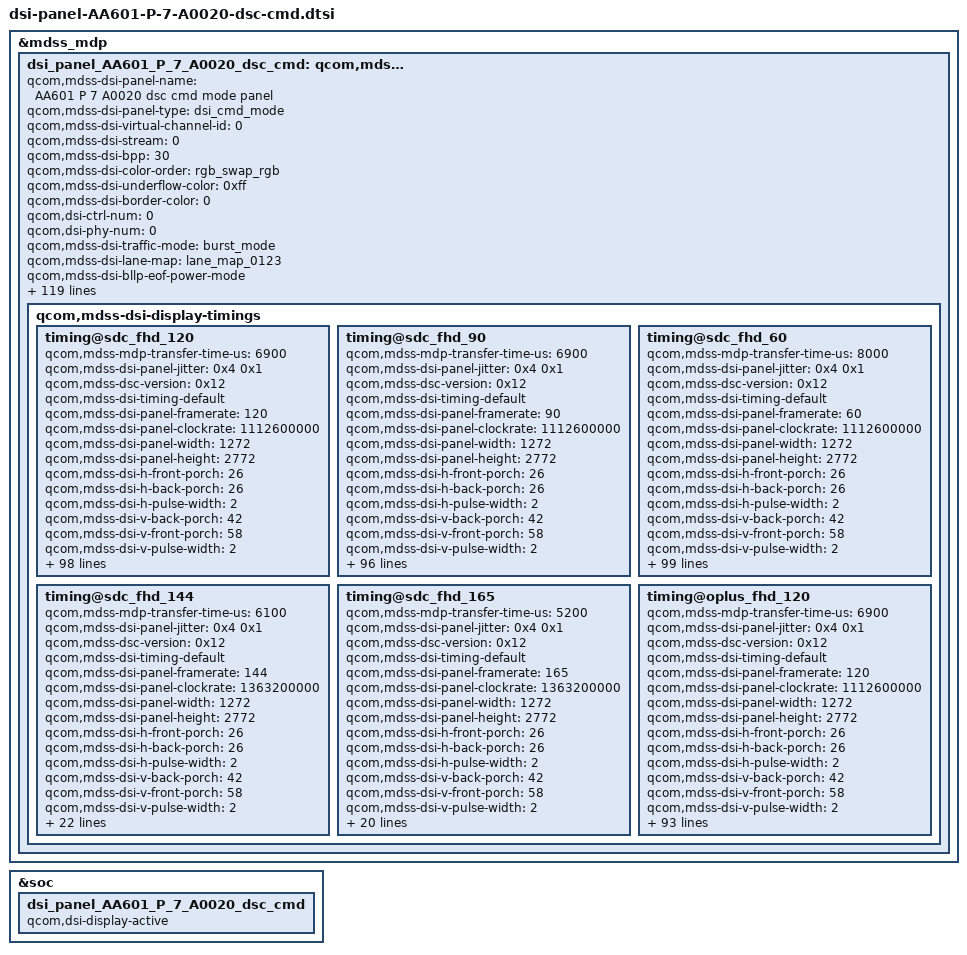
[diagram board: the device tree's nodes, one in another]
&mdss_mdp {
	dsi_panel_AA601_P_7_A0020_dsc_cmd: qcom,mdss_dsi_panel_AA601_P_7_A0020_dsc_cmd {
		qcom,mdss-dsi-panel-name = "AA601 P 7 A0020 dsc cmd mode panel";
		qcom,mdss-dsi-panel-type = "dsi_cmd_mode";
		qcom,mdss-dsi-virtual-channel-id = <0>;
		qcom,mdss-dsi-stream = <0>;
		qcom,mdss-dsi-bpp = <30>;
		qcom,mdss-dsi-color-order = "rgb_swap_rgb";
		qcom,mdss-dsi-underflow-color = <0xff>;
		qcom,mdss-dsi-border-color = <0>;
		qcom,dsi-ctrl-num = <0>;
		qcom,dsi-phy-num = <0>;
		qcom,mdss-dsi-traffic-mode = "burst_mode";
		qcom,mdss-dsi-lane-map = "lane_map_0123";
		qcom,mdss-dsi-bllp-eof-power-mode;
		qcom,mdss-dsi-bllp-power-mode;
		qcom,mdss-dsi-lane-0-state;
		qcom,mdss-dsi-lane-1-state;
		qcom,mdss-dsi-lane-2-state;
		qcom,mdss-dsi-lane-3-state;
		qcom,mdss-dsi-dma-trigger = "trigger_sw";
		qcom,mdss-dsi-dma-schedule-line = <1>;
		qcom,mdss-dsi-dma-schedule-window = <10>;
		qcom,mdss-dsi-mdp-trigger = "none";
		qcom,mdss-dsi-reset-sequence = <1 2>, <0 5>, <1 25>;
		qcom,mdss-dsi-te-pin-select = <1>;
		qcom,mdss-dsi-te-dcs-command = <1>;
		qcom,mdss-pan-physical-width-dimension = <71>;
		qcom,mdss-pan-physical-height-dimension = <157>;
		qcom,mdss-dsi-init-delay-us = <1000>;
		qcom,mdss-dsi-te-check-enable;
		qcom,mdss-dsi-te-using-te-pin;
		qcom,mdss-dsi-lp11-init;
		qcom,mdss-dsi-wr-mem-start = <0x2c>;
		qcom,mdss-dsi-wr-mem-continue = <0x3c>;
		qcom,mdss-dsi-panel-jitter = <0x4 0x1>;
		qcom,mdss-bl-high2bit;
		/* HDR Setting */
		qcom,mdss-dsi-panel-hdr-enabled;
		qcom,mdss-dsi-panel-hdr-color-primaries = <15635 16450 34000 16000 13250 34500 7500 3000>;
		//update for [MPC15]android.mediapc.cts.PerformanceClassTest#testDisplayHdr pass
		//qcom,mdss-dsi-panel-peak-brightness = <5400000>;
		qcom,mdss-dsi-panel-peak-brightness = <20000000>;
		qcom,mdss-dsi-panel-average-brightness = <2000000>;
		qcom,mdss-dsi-panel-blackness-level = <4000>;


		qcom,mdss-dsi-display-timings {
			timing@sdc_fhd_120 {
				#include "dsi-panel-AA601-P-7-A0020-common.dtsi"
				#include "dsi-panel-AA601-P-7-A0020-loading-effect.dtsi"
				qcom,mdss-mdp-transfer-time-us = <6900>;
				qcom,mdss-dsi-panel-jitter = <0x4 0x1>;
				qcom,mdss-dsc-version = <0x12>;
				qcom,mdss-dsi-timing-default;
				qcom,mdss-dsi-panel-framerate = <120>;
				qcom,mdss-dsi-panel-clockrate = <1112600000>;
				qcom,mdss-dsi-panel-width = <1272>;
				qcom,mdss-dsi-panel-height = <2772>;

				qcom,mdss-dsi-h-front-porch = <26>;
				qcom,mdss-dsi-h-back-porch = <26>;
				qcom,mdss-dsi-h-pulse-width = <2>;
				qcom,mdss-dsi-v-back-porch = <42>;
				qcom,mdss-dsi-v-front-porch = <58>;
				qcom,mdss-dsi-v-pulse-width = <2>;
				qcom,mdss-dsi-h-sync-pulse = <0>;

				oplus,ofp-need-to-sync-data-in-aod-unlocking;
				oplus,ofp-aod-off-insert-black-frame = <1>;
				oplus,ofp-aod-off-black-frame-total-time = <42>;
				oplus,ofp-need-to-separate-backlight;
				oplus,ofp-backlight-on-period = <1>;

				qcom,mdss-dsi-timing-switch-command = [
					39 00 00 40 00 00 04 FF 5A A5 00
					15 00 00 40 00 00 02 60 00 //120hz 3 pulse
					15 00 00 40 00 00 02 7D 00
					39 00 00 40 00 00 04 FF 5A A5 2D
					39 00 00 40 00 00 03 83 00 00
					15 00 00 40 00 00 02 F2 00
					39 00 00 00 00 00 04 FF 5A A5 00
				];

				qcom,mdss-dsi-timing-switch-compensation-command = [
					39 00 00 40 00 00 04 FF 5A A5 08 //Page 8
					15 00 00 40 00 00 02 98 02 //Disable CMD FIFO reset
					39 00 00 40 00 00 04 FF 5A A5 4F //Page 4F
					15 00 00 40 00 00 02 81 06
					15 00 00 40 00 00 02 88 78 //MFSC Start
					//D3G
					39 00 00 40 00 00 04 FF 5A A5 24
					39 00 00 40 00 00 06 C9 00 00 00 10 00
					39 00 00 40 00 00 04 FE 30 00 50
					39 00 00 40 00 00 06 CA 00 70 00 B0 01
					39 00 00 40 00 00 04 FE 00 01 30
					39 00 00 40 00 00 06 CB 01 73 01 AD 01
					39 00 00 40 00 00 04 FE F0 02 70
					39 00 00 40 00 00 06 CC 02 F0 03 50 03
					39 00 00 40 00 00 04 FE F0 04 70
					39 00 00 40 00 00 06 CD 04 F0 06 E0 08
					39 00 00 40 00 00 04 FE F0 0A 00
					39 00 00 40 00 00 06 CE 0B A0 0C D0 0D
					39 00 00 40 00 00 04 FE C0 0F F0
					39 00 00 40 00 00 04 FF 5A A5 4F //Page 4F
					15 00 00 40 00 00 02 8A 78 //MFSC Start
					//Mode control
					39 00 00 40 00 00 04 FF 5A A5 00 //Page 0
					15 00 00 40 00 00 02 60 00 //120HZ
					15 00 00 40 00 00 02 7D 00
					39 00 00 40 00 00 04 FF 5A A5 2D //Page 2D
					39 00 00 40 00 00 03 83 00 00 //Skip 0
					15 00 00 40 00 00 02 F2 00
					//D3G
					39 00 00 40 00 00 04 FF 5A A5 24
					39 00 00 40 00 00 06 C9 00 00 00 10 00
					39 00 00 40 00 00 04 FE 30 00 50
					39 00 00 40 00 00 06 CA 00 70 00 B0 00
					39 00 00 40 00 00 04 FE F0 01 30
					39 00 00 40 00 00 06 CB 01 70 01 B0 01
					39 00 00 40 00 00 04 FE F0 02 70
					39 00 00 40 00 00 06 CC 02 F0 03 70 03
					39 00 00 40 00 00 04 FE F0 04 70
					39 00 00 40 00 00 06 CD 04 F0 06 F0 08
					39 00 00 40 00 00 04 FE F0 0A 00
					39 00 00 40 00 00 06 CE 0B A0 0C D0 0E
					39 00 00 40 00 00 04 FE 10 0F F0
					//1 Gamma mode
					39 00 00 40 00 00 04 FF 5A A5 23
					15 00 00 40 00 00 02 CA 00
					15 00 00 40 00 00 02 CE 00
					//1 Gamma mode group
					39 00 00 40 00 00 04 FF 5A A5 24
					15 00 00 40 00 00 02 8D 42
					15 00 00 40 00 00 02 8E 74
					15 00 00 40 00 00 02 8F 50
					15 00 00 40 00 00 02 90 64
					//Normal DMR
					39 00 00 40 00 00 04 FF 5A A5 53
					15 00 00 40 00 00 02 F0 01
					15 00 00 40 00 00 02 00 00
					15 00 00 40 00 00 02 00 00
					15 00 00 40 00 00 02 00 00
					15 00 00 40 00 00 02 00 00
					15 00 00 40 00 00 02 00 00
					15 00 00 40 00 00 02 00 00
					15 00 00 40 00 00 02 00 00
					15 00 00 40 00 00 02 00 00
					39 00 00 40 00 00 04 FF 5A A5 63
					39 00 00 40 00 00 06 F1 20 20 20 20 20
					39 00 00 40 00 00 06 FE 20 00 00 00 00
					39 00 00 40 00 00 06 FE 00 00 00 00 00
					15 00 00 40 00 00 02 FE 00
					15 00 00 40 00 00 02 00 00
					15 00 00 40 00 00 02 00 00
					15 00 00 40 00 00 02 00 00
					15 00 00 40 00 00 02 00 00
					15 00 00 40 00 00 02 00 00
					39 00 00 40 00 00 06 F2 00 00 00 00 00
					39 00 00 40 00 00 06 FE 00 00 00 00 00
					39 00 00 40 00 00 06 FE 00 00 00 00 00
					15 00 00 40 00 00 02 FE 00
					15 00 00 40 00 00 02 00 00
					15 00 00 40 00 00 02 00 00
					15 00 00 40 00 00 02 00 00
					15 00 00 40 00 00 02 00 00
					15 00 00 40 00 00 02 00 00
					39 00 00 40 00 00 06 F3 00 00 00 00 00
					39 00 00 40 00 00 06 FE 00 20 20 20 20
					39 00 00 40 00 00 06 FE 00 00 00 00 00
					15 00 00 40 00 00 02 FE 00
					15 00 00 40 00 00 02 00 00
					15 00 00 40 00 00 02 00 00
					15 00 00 40 00 00 02 00 00
					15 00 00 40 00 00 02 00 00
					15 00 00 40 00 00 02 00 00
					39 00 00 40 00 00 06 F4 00 00 00 00 00
					39 00 00 40 00 00 06 FE 00 F0 F0 F0 F0
					39 00 00 40 00 00 06 FE 00 00 00 00 00
					15 00 00 40 00 00 02 FE 00
					15 00 00 40 00 00 02 00 00
					15 00 00 40 00 00 02 00 00
					15 00 00 40 00 00 02 00 00
					15 00 00 40 00 00 02 00 00
					15 00 00 40 00 00 02 00 00
					15 00 00 40 00 00 02 00 00
					15 00 00 40 00 00 02 00 00
					15 00 00 40 00 00 02 00 00
					39 00 00 40 00 00 04 FF 5A A5 53
					15 00 00 40 00 00 02 F0 00
					39 00 00 40 00 00 04 FF 5A A5 08 //Page 8
					15 00 00 40 00 00 02 98 A6 //Enable CMD FIFO reset
					39 00 00 40 00 00 04 FF 5A A5 00 //Page 0
					15 00 00 40 00 00 02 00 00 //Dummy write
					39 00 00 40 00 00 04 FF 5A A5 4F //Page 4F
					15 00 00 40 00 00 02 8B 78 //MFSC All done
					39 00 00 00 00 00 04 FF 5A A5 00
					/* wait for te and blocking one frame */
					39 00 00 20 00 00 04 FF 5A A5 00
				];

				qcom,mdss-dsi-on-command = [
					39 00 00 40 00 00 04 FF 5A A5 13
					15 00 00 40 00 00 02 F9 4C //HOLE OFF
					39 00 00 40 00 00 04 FF 5A A5 17
					15 00 00 40 00 00 02 A0 0E //RCN OFF
					//SPR in AP Start
					39 00 00 40 00 00 04 FF 5A A5 07
					15 00 00 40 00 00 02 8A 01
					39 00 00 40 00 00 03 8B 21 E0
					39 00 00 40 00 00 64 80 00 00 00 00 00 12 00 00 AB 30 80 0A D4 04 F8 00 16 02 7C 02 7C 02 00 02 59 00 20 02 2E 00 08 00 0D 04 F4 03 ED 18 00 10 F0 07 10 20 00 06 0F 0F 33 0E 1C 2A 38 46 54 62 69 70 77 79 7B 7D 7E 02 02 22 00 2A 40 2A BE 3A FC 3A FA 3A F8 3B 38 3B 78 3B B6 4B B6 4B F4 4B F4 6C 34 84 74 00 00 00 00 00 00
					39 00 00 40 00 00 64 81 00 00 00 00 00 12 00 00 AB 21 00 0A D4 04 F8 00 16 02 7C 02 7C 01 55 01 D7 00 0A 01 2D 00 35 00 0D 04 F4 16 3B 08 00 0C 00 07 10 20 00 06 0F 0F 33 0E 1C 2A 38 46 54 62 69 70 77 79 7B 7D 7E 00 82 11 40 19 C0 22 3E 32 7C 3A BA 3A F8 3B 38 3B 38 3B 76 4B 76 4B 74 4B 74 5B B4 73 F4 01 00 00 00 00 00
					39 00 00 40 00 00 04 FF 5A A5 07
					15 00 00 40 00 00 02 91 03 //Ycrcb
					39 00 00 40 00 00 04 FF 5A A5 14
					15 00 00 40 00 00 02 82 01 //SPR IN AP  ON
					39 00 00 40 00 00 04 FF 5A A5 14
					15 00 00 40 00 00 02 80 00 //DDIC SPR OFF
					//SPR in AP END
					39 00 00 40 00 00 04 FF 5A A5 4F
					15 00 00 40 00 00 02 81 06 //CMDQ SETTING
					39 00 00 40 00 00 04 FF 5A A5 08
					15 00 00 40 00 00 02 C8 62 //OTP don’t reload
					39 00 00 40 00 00 04 FF 5A A5 21
					15 00 00 40 00 00 02 A4 38 //Flash reload
					39 00 00 40 00 00 04 FF 5A A5 23
					15 00 00 40 00 00 02 85 15 //BC reload by OTP
					39 00 00 40 00 00 04 FF 5A A5 01
					15 00 00 40 00 00 02 FB 08 //Multi TE
					39 00 00 40 00 00 04 FF 5A A5 06
					15 00 00 40 00 00 02 A0 00 //ESD fixed
					15 00 00 40 00 00 02 C6 01 //1bit ESD check
					39 00 00 40 00 00 04 FF 5A A5 08
					15 00 00 40 00 00 02 D2 05
					15 00 00 40 00 00 02 D3 01
					/* FFC Setting */
					39 00 00 40 00 00 04 FF 5A A5 22
					39 00 00 40 00 00 08 D8 01 00 11 10 3C 18 18 //120HZ
					39 00 00 40 00 00 08 D9 00 FC 11 10 30 18 18 //144/165Hz
					39 00 00 40 00 00 0A DC 84 94 BB 00 20 C4 A1 CC 10
					15 00 00 40 00 00 02 DD 01
					15 00 00 40 00 00 02 DE F1
					15 00 00 40 00 00 02 DF 80
					39 00 00 40 00 00 07 E0 02 00 5F 21 00 28
					39 00 00 40 00 00 04 FF 5A A5 00
					15 00 00 40 00 00 02 7D 00
					39 00 00 40 00 00 04 FF 5A A5 00
					15 00 00 40 00 00 02 5E 01
					15 00 00 40 00 00 02 60 00
					15 00 00 40 00 00 02 61 07
					15 00 00 40 00 00 02 6D 01
					05 00 00 40 00 00 01 35
					15 00 00 00 00 00 02 53 20
					39 00 00 40 00 00 04 FF 5A A5 2D
					39 00 00 40 00 00 04 EC 01 FF 00 //SF en
					39 00 00 40 00 00 03 94 F5 00 // 144Hz SF mode2  165hz SF mode4
					39 00 00 00 00 00 04 FF 5A A5 00

					/* SC6027 */
					39 00 00 40 00 00 04 FF 5A A5 20
					15 00 00 40 00 00 02 C8 00
					15 00 00 40 00 00 02 C7 00
					39 00 00 40 00 00 04 FF 5A A5 00
					39 00 00 40 00 00 05 94 00 D0 00 00
					39 00 00 40 00 00 04 FF 5A A5 1F
					15 00 00 40 00 00 02 87 09
					15 00 00 40 00 00 02 88 34
					39 00 00 40 00 00 05 89 41 00 C4 01
					39 00 00 40 00 00 03 8A 8C 14
					39 00 00 40 00 00 05 8C 80 07 00 40
					15 00 00 40 00 00 02 8E 10
					15 00 00 40 00 00 02 95 00
					39 00 00 40 00 00 05 96 15 35 55 01
					39 00 00 40 00 00 19 83 00 0B 0A 0C 02 0F FF FF 0C 02 FF FF 00 FF 00 0B 00 FF FF FF FF FF FF FF
					39 00 00 40 00 00 19 8F 03 30 8C 19 0F 18 00 00 19 0F 00 00 00 00 02 30 02 00 00 00 00 00 00 00
					39 00 00 40 00 00 09 85 00 0B 0A FF FF FF FF FF
					39 00 00 40 00 00 09 91 03 30 24 00 00 00 00 00
					39 00 00 40 00 00 04 FF 5A A5 29
					39 00 00 40 00 00 09 82 74 2C 2A 2A 28 28 26 26
					39 00 00 40 00 00 09 83 24 24 22 22 20 20 1E 1E
					39 00 00 40 00 00 09 84 1C 1C 1A 1A 18 18 18 18
					39 00 00 40 00 00 07 85 18 18 18 18 18 18
					39 00 00 00 00 00 04 FF 5A A5 00
					/* 120hz 3 pulse */
					39 00 00 40 00 00 04 FF 5A A5 00
					15 00 00 40 00 00 02 60 00 //120hz 3 pulse
					15 00 00 40 00 00 02 7D 00
					39 00 00 40 00 00 04 FF 5A A5 2D
					39 00 00 40 00 00 03 83 00 00
					15 00 00 40 00 00 02 F2 00
					39 00 00 00 00 00 04 FF 5A A5 00

					05 00 00 00 78 00 01 11
					05 00 00 00 14 00 01 29
				];
			};
			timing@sdc_fhd_90 {
				#include "dsi-panel-AA601-P-7-A0020-common.dtsi"
				#include "dsi-panel-AA601-P-7-A0020-loading-effect.dtsi"
				qcom,mdss-mdp-transfer-time-us = <6900>;
				qcom,mdss-dsi-panel-jitter = <0x4 0x1>;
				qcom,mdss-dsc-version = <0x12>;
				qcom,mdss-dsi-timing-default;
				qcom,mdss-dsi-panel-framerate = <90>;
				qcom,mdss-dsi-panel-clockrate = <1112600000>;
				qcom,mdss-dsi-panel-width = <1272>;
				qcom,mdss-dsi-panel-height = <2772>;

				qcom,mdss-dsi-h-front-porch = <26>;
				qcom,mdss-dsi-h-back-porch = <26>;
				qcom,mdss-dsi-h-pulse-width = <2>;
				qcom,mdss-dsi-v-back-porch = <42>;
				qcom,mdss-dsi-v-front-porch = <58>;
				qcom,mdss-dsi-v-pulse-width = <2>;
				qcom,mdss-dsi-h-sync-pulse = <0>;

				oplus,ofp-need-to-sync-data-in-aod-unlocking;
				oplus,ofp-aod-off-insert-black-frame = <1>;
				oplus,ofp-aod-off-black-frame-total-time = <42>;
				oplus,ofp-need-to-separate-backlight;
				oplus,ofp-backlight-on-period = <1>;

				qcom,mdss-dsi-timing-switch-command = [
					39 00 00 40 00 00 04 FF 5A A5 00
					15 00 00 40 00 00 02 60 02 //90hz 3 pulse
					15 00 00 40 00 00 02 7D 00
					39 00 00 40 00 00 04 FF 5A A5 2D
					39 00 00 40 00 00 03 85 00 00
					39 00 00 00 00 00 04 FF 5A A5 00
				];

				qcom,mdss-dsi-timing-switch-compensation-command = [
					39 00 00 40 00 00 04 FF 5A A5 08 //Page 8
					15 00 00 40 00 00 02 98 02 //Disable CMD FIFO reset
					39 00 00 40 00 00 04 FF 5A A5 4F //Page 4F
					15 00 00 40 00 00 02 81 06
					15 00 00 40 00 00 02 88 78 //MFSC Start
					//D3G
					39 00 00 40 00 00 04 FF 5A A5 24
					39 00 00 40 00 00 06 C9 00 00 00 10 00
					39 00 00 40 00 00 04 FE 30 00 50
					39 00 00 40 00 00 06 CA 00 70 00 B0 01
					39 00 00 40 00 00 04 FE 00 01 30
					39 00 00 40 00 00 06 CB 01 73 01 AD 01
					39 00 00 40 00 00 04 FE F0 02 70
					39 00 00 40 00 00 06 CC 02 F0 03 50 03
					39 00 00 40 00 00 04 FE F0 04 70
					39 00 00 40 00 00 06 CD 04 F0 06 E0 08
					39 00 00 40 00 00 04 FE F0 0A 00
					39 00 00 40 00 00 06 CE 0B A0 0C D0 0D
					39 00 00 40 00 00 04 FE C0 0F F0
					39 00 00 40 00 00 04 FF 5A A5 4F //Page 4F
					15 00 00 40 00 00 02 8A 78 //MFSC Start
					//Mode control
					39 00 00 40 00 00 04 FF 5A A5 00 //Page 0
					15 00 00 40 00 00 02 60 02 //90HZ
					15 00 00 40 00 00 02 7D 00
					39 00 00 40 00 00 04 FF 5A A5 2D //Page 2D
					39 00 00 40 00 00 03 85 00 00 //Skip 0
					//D3G
					39 00 00 40 00 00 04 FF 5A A5 24
					39 00 00 40 00 00 06 C9 00 00 00 10 00
					39 00 00 40 00 00 04 FE 30 00 50
					39 00 00 40 00 00 06 CA 00 70 00 B0 00
					39 00 00 40 00 00 04 FE F0 01 30
					39 00 00 40 00 00 06 CB 01 70 01 B0 01
					39 00 00 40 00 00 04 FE F0 02 70
					39 00 00 40 00 00 06 CC 02 F0 03 70 03
					39 00 00 40 00 00 04 FE F0 04 70
					39 00 00 40 00 00 06 CD 04 F0 06 F0 08
					39 00 00 40 00 00 04 FE F0 0A 00
					39 00 00 40 00 00 06 CE 0B A0 0C D0 0E
					39 00 00 40 00 00 04 FE 10 0F F0
					//1 Gamma mode
					39 00 00 40 00 00 04 FF 5A A5 23
					15 00 00 40 00 00 02 CA 00
					15 00 00 40 00 00 02 CE 00
					//1 Gamma mode group
					39 00 00 40 00 00 04 FF 5A A5 24
					15 00 00 40 00 00 02 8D 42
					15 00 00 40 00 00 02 8E 74
					15 00 00 40 00 00 02 8F 50
					15 00 00 40 00 00 02 90 64
					//Normal DMR
					39 00 00 40 00 00 04 FF 5A A5 53
					15 00 00 40 00 00 02 F0 01
					15 00 00 40 00 00 02 00 00
					15 00 00 40 00 00 02 00 00
					15 00 00 40 00 00 02 00 00
					15 00 00 40 00 00 02 00 00
					15 00 00 40 00 00 02 00 00
					15 00 00 40 00 00 02 00 00
					15 00 00 40 00 00 02 00 00
					15 00 00 40 00 00 02 00 00
					39 00 00 40 00 00 04 FF 5A A5 63
					39 00 00 40 00 00 06 F1 20 20 20 20 20
					39 00 00 40 00 00 06 FE 20 00 00 00 00
					39 00 00 40 00 00 06 FE 00 00 00 00 00
					15 00 00 40 00 00 02 FE 00
					15 00 00 40 00 00 02 00 00
					15 00 00 40 00 00 02 00 00
					15 00 00 40 00 00 02 00 00
					15 00 00 40 00 00 02 00 00
					15 00 00 40 00 00 02 00 00
					39 00 00 40 00 00 06 F2 00 00 00 00 00
					39 00 00 40 00 00 06 FE 00 00 00 00 00
					39 00 00 40 00 00 06 FE 00 00 00 00 00
					15 00 00 40 00 00 02 FE 00
					15 00 00 40 00 00 02 00 00
					15 00 00 40 00 00 02 00 00
					15 00 00 40 00 00 02 00 00
					15 00 00 40 00 00 02 00 00
					15 00 00 40 00 00 02 00 00
					39 00 00 40 00 00 06 F3 00 00 00 00 00
					39 00 00 40 00 00 06 FE 00 20 20 20 20
					39 00 00 40 00 00 06 FE 00 00 00 00 00
					15 00 00 40 00 00 02 FE 00
					15 00 00 40 00 00 02 00 00
					15 00 00 40 00 00 02 00 00
					15 00 00 40 00 00 02 00 00
					15 00 00 40 00 00 02 00 00
					15 00 00 40 00 00 02 00 00
					39 00 00 40 00 00 06 F4 00 00 00 00 00
					39 00 00 40 00 00 06 FE 00 F0 F0 F0 F0
					39 00 00 40 00 00 06 FE 00 00 00 00 00
					15 00 00 40 00 00 02 FE 00
					15 00 00 40 00 00 02 00 00
					15 00 00 40 00 00 02 00 00
					15 00 00 40 00 00 02 00 00
					15 00 00 40 00 00 02 00 00
					15 00 00 40 00 00 02 00 00
					15 00 00 40 00 00 02 00 00
					15 00 00 40 00 00 02 00 00
					15 00 00 40 00 00 02 00 00
					39 00 00 40 00 00 04 FF 5A A5 53
					15 00 00 40 00 00 02 F0 00
					39 00 00 40 00 00 04 FF 5A A5 08 //Page 8
					15 00 00 40 00 00 02 98 A6 //Enable CMD FIFO reset
					39 00 00 40 00 00 04 FF 5A A5 00 //Page 0
					15 00 00 40 00 00 02 00 00 //Dummy write
					39 00 00 40 00 00 04 FF 5A A5 4F //Page 4F
					15 00 00 40 00 00 02 8B 78 //MFSC All done
					39 00 00 00 00 00 04 FF 5A A5 00
					/* wait for te and blocking one frame */
					39 00 00 20 00 00 04 FF 5A A5 00
				];

				qcom,mdss-dsi-on-command = [
					39 00 00 40 00 00 04 FF 5A A5 13
					15 00 00 40 00 00 02 F9 4C //HOLE OFF
					39 00 00 40 00 00 04 FF 5A A5 17
					15 00 00 40 00 00 02 A0 0E //RCN OFF
					//SPR in AP Start
					39 00 00 40 00 00 04 FF 5A A5 07
					15 00 00 40 00 00 02 8A 01
					39 00 00 40 00 00 03 8B 21 E0
					39 00 00 40 00 00 64 80 00 00 00 00 00 12 00 00 AB 30 80 0A D4 04 F8 00 16 02 7C 02 7C 02 00 02 59 00 20 02 2E 00 08 00 0D 04 F4 03 ED 18 00 10 F0 07 10 20 00 06 0F 0F 33 0E 1C 2A 38 46 54 62 69 70 77 79 7B 7D 7E 02 02 22 00 2A 40 2A BE 3A FC 3A FA 3A F8 3B 38 3B 78 3B B6 4B B6 4B F4 4B F4 6C 34 84 74 00 00 00 00 00 00
					39 00 00 40 00 00 64 81 00 00 00 00 00 12 00 00 AB 21 00 0A D4 04 F8 00 16 02 7C 02 7C 01 55 01 D7 00 0A 01 2D 00 35 00 0D 04 F4 16 3B 08 00 0C 00 07 10 20 00 06 0F 0F 33 0E 1C 2A 38 46 54 62 69 70 77 79 7B 7D 7E 00 82 11 40 19 C0 22 3E 32 7C 3A BA 3A F8 3B 38 3B 38 3B 76 4B 76 4B 74 4B 74 5B B4 73 F4 01 00 00 00 00 00
					39 00 00 40 00 00 04 FF 5A A5 07
					15 00 00 40 00 00 02 91 03 //Ycrcb
					39 00 00 40 00 00 04 FF 5A A5 14
					15 00 00 40 00 00 02 82 01 //SPR IN AP  ON
					39 00 00 40 00 00 04 FF 5A A5 14
					15 00 00 40 00 00 02 80 00 //DDIC SPR OFF
					//SPR in AP END
					39 00 00 40 00 00 04 FF 5A A5 4F
					15 00 00 40 00 00 02 81 06 //CMDQ SETTING
					39 00 00 40 00 00 04 FF 5A A5 08
					15 00 00 40 00 00 02 C8 62 //OTP don’t reload
					39 00 00 40 00 00 04 FF 5A A5 21
					15 00 00 40 00 00 02 A4 38 //Flash reload
					39 00 00 40 00 00 04 FF 5A A5 23
					15 00 00 40 00 00 02 85 15 //BC reload by OTP
					39 00 00 40 00 00 04 FF 5A A5 01
					15 00 00 40 00 00 02 FB 08 //Multi TE
					39 00 00 40 00 00 04 FF 5A A5 06
					15 00 00 40 00 00 02 A0 00 //ESD fixed
					15 00 00 40 00 00 02 C6 01 //1bit ESD check
					39 00 00 40 00 00 04 FF 5A A5 08
					15 00 00 40 00 00 02 D2 05
					15 00 00 40 00 00 02 D3 01
					/* FFC Setting */
					39 00 00 40 00 00 04 FF 5A A5 22
					39 00 00 40 00 00 08 D8 01 00 11 10 3C 18 18 //120HZ
					39 00 00 40 00 00 08 D9 00 FC 11 10 30 18 18 //144/165Hz
					39 00 00 40 00 00 0A DC 84 94 BB 00 20 C4 A1 CC 10
					15 00 00 40 00 00 02 DD 01
					15 00 00 40 00 00 02 DE F1
					15 00 00 40 00 00 02 DF 80
					39 00 00 40 00 00 07 E0 02 00 5F 21 00 28
					39 00 00 40 00 00 04 FF 5A A5 00
					15 00 00 40 00 00 02 7D 00
					39 00 00 40 00 00 04 FF 5A A5 00
					15 00 00 40 00 00 02 5E 01
					15 00 00 40 00 00 02 60 00
					15 00 00 40 00 00 02 61 07
					15 00 00 40 00 00 02 6D 01
					05 00 00 40 00 00 01 35
					15 00 00 00 00 00 02 53 20
					39 00 00 40 00 00 04 FF 5A A5 2D
					39 00 00 40 00 00 04 EC 01 FF 00 //SF en
					39 00 00 40 00 00 03 94 F5 00 // 144Hz SF mode2  165hz SF mode4
					39 00 00 00 00 00 04 FF 5A A5 00

					/* SC6027 */
					39 00 00 40 00 00 04 FF 5A A5 20
					15 00 00 40 00 00 02 C8 00
					15 00 00 40 00 00 02 C7 00
					39 00 00 40 00 00 04 FF 5A A5 00
					39 00 00 40 00 00 05 94 00 D0 00 00
					39 00 00 40 00 00 04 FF 5A A5 1F
					15 00 00 40 00 00 02 87 09
					15 00 00 40 00 00 02 88 34
					39 00 00 40 00 00 05 89 41 00 C4 01
					39 00 00 40 00 00 03 8A 8C 14
					39 00 00 40 00 00 05 8C 80 07 00 40
					15 00 00 40 00 00 02 8E 10
					15 00 00 40 00 00 02 95 00
					39 00 00 40 00 00 05 96 15 35 55 01
					39 00 00 40 00 00 19 83 00 0B 0A 0C 02 0F FF FF 0C 02 FF FF 00 FF 00 0B 00 FF FF FF FF FF FF FF
					39 00 00 40 00 00 19 8F 03 30 8C 19 0F 18 00 00 19 0F 00 00 00 00 02 30 02 00 00 00 00 00 00 00
					39 00 00 40 00 00 09 85 00 0B 0A FF FF FF FF FF
					39 00 00 40 00 00 09 91 03 30 24 00 00 00 00 00
					39 00 00 40 00 00 04 FF 5A A5 29
					39 00 00 40 00 00 09 82 74 2C 2A 2A 28 28 26 26
					39 00 00 40 00 00 09 83 24 24 22 22 20 20 1E 1E
					39 00 00 40 00 00 09 84 1C 1C 1A 1A 18 18 18 18
					39 00 00 40 00 00 07 85 18 18 18 18 18 18
					39 00 00 00 00 00 04 FF 5A A5 00
					/* 90hz 3 pulse */
					39 00 00 40 00 00 04 FF 5A A5 00
					15 00 00 40 00 00 02 60 02 //90hz 3 pulse
					15 00 00 40 00 00 02 7D 00
					39 00 00 40 00 00 04 FF 5A A5 2D
					39 00 00 40 00 00 03 85 00 00
					39 00 00 00 00 00 04 FF 5A A5 00

					05 00 00 00 78 00 01 11
					05 00 00 00 14 00 01 29
				];
			};
			timing@sdc_fhd_60 {
				#include "dsi-panel-AA601-P-7-A0020-common.dtsi"
				#include "dsi-panel-AA601-P-7-A0020-loading-effect.dtsi"
				qcom,mdss-mdp-transfer-time-us = <8000>;
				qcom,mdss-dsi-panel-jitter = <0x4 0x1>;
				qcom,mdss-dsc-version = <0x12>;
				qcom,mdss-dsi-timing-default;
				qcom,mdss-dsi-panel-framerate = <60>;
				qcom,mdss-dsi-panel-clockrate = <1112600000>;
				qcom,mdss-dsi-panel-width = <1272>;
				qcom,mdss-dsi-panel-height = <2772>;

				qcom,mdss-dsi-h-front-porch = <26>;
				qcom,mdss-dsi-h-back-porch = <26>;
				qcom,mdss-dsi-h-pulse-width = <2>;
				qcom,mdss-dsi-v-back-porch = <42>;
				qcom,mdss-dsi-v-front-porch = <58>;
				qcom,mdss-dsi-v-pulse-width = <2>;
				qcom,mdss-dsi-h-sync-pulse = <0>;

				oplus,ofp-need-to-sync-data-in-aod-unlocking;
				oplus,ofp-aod-off-insert-black-frame = <1>;
				oplus,ofp-aod-off-black-frame-total-time = <42>;
				oplus,ofp-need-to-separate-backlight;
				oplus,ofp-backlight-on-period = <1>;
				oplus,apollo-panel-async-bl-delay = <9000>;
				oplus,apollo-panel-vsync-width = <9000>;
				oplus,panel-pwm-switch-frame-delay = <9000>;

				qcom,mdss-dsi-timing-switch-command = [
					39 00 00 40 00 00 04 FF 5A A5 00
					15 00 00 40 00 00 02 60 00
					15 00 00 40 00 00 02 7D 00
					39 00 00 40 00 00 04 FF 5A A5 2D
					39 00 00 40 00 00 03 83 01 00
					15 00 00 40 00 00 02 F2 01
					39 00 00 00 00 00 04 FF 5A A5 00
				];

				qcom,mdss-dsi-timing-switch-compensation-command = [
					39 00 00 40 00 00 04 FF 5A A5 08 //Page 8
					15 00 00 40 00 00 02 98 02 //Disable CMD FIFO reset
					39 00 00 40 00 00 04 FF 5A A5 4F //Page 4F
					15 00 00 40 00 00 02 81 06
					15 00 00 40 00 00 02 88 78 //MFSC Start
					//D3G
					39 00 00 40 00 00 04 FF 5A A5 24
					39 00 00 40 00 00 06 C9 00 00 00 10 00
					39 00 00 40 00 00 04 FE 30 00 50
					39 00 00 40 00 00 06 CA 00 70 00 B0 01
					39 00 00 40 00 00 04 FE 00 01 30
					39 00 00 40 00 00 06 CB 01 73 01 AD 01
					39 00 00 40 00 00 04 FE F0 02 70
					39 00 00 40 00 00 06 CC 02 F0 03 50 03
					39 00 00 40 00 00 04 FE F0 04 70
					39 00 00 40 00 00 06 CD 04 F0 06 E0 08
					39 00 00 40 00 00 04 FE F0 0A 00
					39 00 00 40 00 00 06 CE 0B A0 0C D0 0D
					39 00 00 40 00 00 04 FE C0 0F F0
					39 00 00 40 00 00 04 FF 5A A5 4F //Page 4F
					15 00 00 40 00 00 02 8A 78 //MFSC Start
					//Mode control
					39 00 00 40 00 00 04 FF 5A A5 00 //Page 0
					15 00 00 40 00 00 02 60 00 //120HZ
					15 00 00 40 00 00 02 7D 00
					39 00 00 40 00 00 04 FF 5A A5 2D //Page 2D
					39 00 00 40 00 00 03 83 01 00 //Skip 60 Hz
					15 00 00 40 00 00 02 F2 01
					//D3G
					39 00 00 40 00 00 04 FF 5A A5 24
					39 00 00 40 00 00 06 C9 00 00 00 10 00
					39 00 00 40 00 00 04 FE 30 00 50
					39 00 00 40 00 00 06 CA 00 70 00 B0 00
					39 00 00 40 00 00 04 FE F0 01 30
					39 00 00 40 00 00 06 CB 01 70 01 B0 01
					39 00 00 40 00 00 04 FE F0 02 70
					39 00 00 40 00 00 06 CC 02 F0 03 70 03
					39 00 00 40 00 00 04 FE F0 04 70
					39 00 00 40 00 00 06 CD 04 F0 06 F0 08
					39 00 00 40 00 00 04 FE F0 0A 00
					39 00 00 40 00 00 06 CE 0B A0 0C D0 0E
					39 00 00 40 00 00 04 FE 10 0F F0
					//1 Gamma mode
					39 00 00 40 00 00 04 FF 5A A5 23
					15 00 00 40 00 00 02 CA 00
					15 00 00 40 00 00 02 CE 00
					//1 Gamma mode group
					39 00 00 40 00 00 04 FF 5A A5 24
					15 00 00 40 00 00 02 8D 42
					15 00 00 40 00 00 02 8E 74
					15 00 00 40 00 00 02 8F 50
					15 00 00 40 00 00 02 90 64
					//Normal DMR
					39 00 00 40 00 00 04 FF 5A A5 53
					15 00 00 40 00 00 02 F0 01
					15 00 00 40 00 00 02 00 00
					15 00 00 40 00 00 02 00 00
					15 00 00 40 00 00 02 00 00
					15 00 00 40 00 00 02 00 00
					15 00 00 40 00 00 02 00 00
					15 00 00 40 00 00 02 00 00
					15 00 00 40 00 00 02 00 00
					15 00 00 40 00 00 02 00 00
					39 00 00 40 00 00 04 FF 5A A5 63
					39 00 00 40 00 00 06 F1 20 20 20 20 20
					39 00 00 40 00 00 06 FE 20 00 00 00 00
					39 00 00 40 00 00 06 FE 00 00 00 00 00
					15 00 00 40 00 00 02 FE 00
					15 00 00 40 00 00 02 00 00
					15 00 00 40 00 00 02 00 00
					15 00 00 40 00 00 02 00 00
					15 00 00 40 00 00 02 00 00
					15 00 00 40 00 00 02 00 00
					39 00 00 40 00 00 06 F2 00 00 00 00 00
					39 00 00 40 00 00 06 FE 00 00 00 00 00
					39 00 00 40 00 00 06 FE 00 00 00 00 00
					15 00 00 40 00 00 02 FE 00
					15 00 00 40 00 00 02 00 00
					15 00 00 40 00 00 02 00 00
					15 00 00 40 00 00 02 00 00
					15 00 00 40 00 00 02 00 00
					15 00 00 40 00 00 02 00 00
					39 00 00 40 00 00 06 F3 00 00 00 00 00
					39 00 00 40 00 00 06 FE 00 20 20 20 20
					39 00 00 40 00 00 06 FE 00 00 00 00 00
					15 00 00 40 00 00 02 FE 00
					15 00 00 40 00 00 02 00 00
					15 00 00 40 00 00 02 00 00
					15 00 00 40 00 00 02 00 00
					15 00 00 40 00 00 02 00 00
					15 00 00 40 00 00 02 00 00
					39 00 00 40 00 00 06 F4 00 00 00 00 00
					39 00 00 40 00 00 06 FE 00 F0 F0 F0 F0
					39 00 00 40 00 00 06 FE 00 00 00 00 00
					15 00 00 40 00 00 02 FE 00
					15 00 00 40 00 00 02 00 00
					15 00 00 40 00 00 02 00 00
					15 00 00 40 00 00 02 00 00
					15 00 00 40 00 00 02 00 00
					15 00 00 40 00 00 02 00 00
					15 00 00 40 00 00 02 00 00
					15 00 00 40 00 00 02 00 00
					15 00 00 40 00 00 02 00 00
					39 00 00 40 00 00 04 FF 5A A5 53
					15 00 00 40 00 00 02 F0 00
					39 00 00 40 00 00 04 FF 5A A5 08 //Page 8
					15 00 00 40 00 00 02 98 A6 //Enable CMD FIFO reset
					39 00 00 40 00 00 04 FF 5A A5 00 //Page 0
					15 00 00 40 00 00 02 00 00 //Dummy write
					39 00 00 40 00 00 04 FF 5A A5 4F //Page 4F
					15 00 00 40 00 00 02 8B 78 //MFSC All done
					39 00 00 00 00 00 04 FF 5A A5 00
					/* wait for te and blocking one frame */
					39 00 00 20 00 00 04 FF 5A A5 00
				];

				qcom,mdss-dsi-on-command = [
					39 00 00 40 00 00 04 FF 5A A5 13
					15 00 00 40 00 00 02 F9 4C //HOLE OFF
					39 00 00 40 00 00 04 FF 5A A5 17
					15 00 00 40 00 00 02 A0 0E //RCN OFF
					//SPR in AP Start
					39 00 00 40 00 00 04 FF 5A A5 07
					15 00 00 40 00 00 02 8A 01
					39 00 00 40 00 00 03 8B 21 E0
					39 00 00 40 00 00 64 80 00 00 00 00 00 12 00 00 AB 30 80 0A D4 04 F8 00 16 02 7C 02 7C 02 00 02 59 00 20 02 2E 00 08 00 0D 04 F4 03 ED 18 00 10 F0 07 10 20 00 06 0F 0F 33 0E 1C 2A 38 46 54 62 69 70 77 79 7B 7D 7E 02 02 22 00 2A 40 2A BE 3A FC 3A FA 3A F8 3B 38 3B 78 3B B6 4B B6 4B F4 4B F4 6C 34 84 74 00 00 00 00 00 00
					39 00 00 40 00 00 64 81 00 00 00 00 00 12 00 00 AB 21 00 0A D4 04 F8 00 16 02 7C 02 7C 01 55 01 D7 00 0A 01 2D 00 35 00 0D 04 F4 16 3B 08 00 0C 00 07 10 20 00 06 0F 0F 33 0E 1C 2A 38 46 54 62 69 70 77 79 7B 7D 7E 00 82 11 40 19 C0 22 3E 32 7C 3A BA 3A F8 3B 38 3B 38 3B 76 4B 76 4B 74 4B 74 5B B4 73 F4 01 00 00 00 00 00
					39 00 00 40 00 00 04 FF 5A A5 07
					15 00 00 40 00 00 02 91 03 //Ycrcb
					39 00 00 40 00 00 04 FF 5A A5 14
					15 00 00 40 00 00 02 82 01 //SPR IN AP  ON
					39 00 00 40 00 00 04 FF 5A A5 14
					15 00 00 40 00 00 02 80 00 //DDIC SPR OFF
					//SPR in AP END
					39 00 00 40 00 00 04 FF 5A A5 4F
					15 00 00 40 00 00 02 81 06 //CMDQ SETTING
					39 00 00 40 00 00 04 FF 5A A5 08
					15 00 00 40 00 00 02 C8 62 //OTP don’t reload
					39 00 00 40 00 00 04 FF 5A A5 21
					15 00 00 40 00 00 02 A4 38 //Flash reload
					39 00 00 40 00 00 04 FF 5A A5 23
					15 00 00 40 00 00 02 85 15 //BC reload by OTP
					39 00 00 40 00 00 04 FF 5A A5 01
					15 00 00 40 00 00 02 FB 08 //Multi TE
					39 00 00 40 00 00 04 FF 5A A5 06
					15 00 00 40 00 00 02 A0 00 //ESD fixed
					15 00 00 40 00 00 02 C6 01 //1bit ESD check
					39 00 00 40 00 00 04 FF 5A A5 08
					15 00 00 40 00 00 02 D2 05
					15 00 00 40 00 00 02 D3 01
					/* FFC Setting */
					39 00 00 40 00 00 04 FF 5A A5 22
					39 00 00 40 00 00 08 D8 01 00 11 10 3C 18 18 //120HZ
					39 00 00 40 00 00 08 D9 00 FC 11 10 30 18 18 //144/165Hz
					39 00 00 40 00 00 0A DC 84 94 BB 00 20 C4 A1 CC 10
					15 00 00 40 00 00 02 DD 01
					15 00 00 40 00 00 02 DE F1
					15 00 00 40 00 00 02 DF 80
					39 00 00 40 00 00 07 E0 02 00 5F 21 00 28
					39 00 00 40 00 00 04 FF 5A A5 00
					15 00 00 40 00 00 02 7D 00
					39 00 00 40 00 00 04 FF 5A A5 00
					15 00 00 40 00 00 02 5E 01
					15 00 00 40 00 00 02 60 00
					15 00 00 40 00 00 02 61 07
					15 00 00 40 00 00 02 6D 01
					05 00 00 40 00 00 01 35
					15 00 00 00 00 00 02 53 20
					39 00 00 40 00 00 04 FF 5A A5 2D
					39 00 00 40 00 00 04 EC 01 FF 00 //SF en
					39 00 00 40 00 00 03 94 F5 00 // 144Hz SF mode2  165hz SF mode4
					39 00 00 00 00 00 04 FF 5A A5 00

					/* SC6027 */
					39 00 00 40 00 00 04 FF 5A A5 20
					15 00 00 40 00 00 02 C8 00
					15 00 00 40 00 00 02 C7 00
					39 00 00 40 00 00 04 FF 5A A5 00
					39 00 00 40 00 00 05 94 00 D0 00 00
					39 00 00 40 00 00 04 FF 5A A5 1F
					15 00 00 40 00 00 02 87 09
					15 00 00 40 00 00 02 88 34
					39 00 00 40 00 00 05 89 41 00 C4 01
					39 00 00 40 00 00 03 8A 8C 14
					39 00 00 40 00 00 05 8C 80 07 00 40
					15 00 00 40 00 00 02 8E 10
					15 00 00 40 00 00 02 95 00
					39 00 00 40 00 00 05 96 15 35 55 01
					39 00 00 40 00 00 19 83 00 0B 0A 0C 02 0F FF FF 0C 02 FF FF 00 FF 00 0B 00 FF FF FF FF FF FF FF
					39 00 00 40 00 00 19 8F 03 30 8C 19 0F 18 00 00 19 0F 00 00 00 00 02 30 02 00 00 00 00 00 00 00
					39 00 00 40 00 00 09 85 00 0B 0A FF FF FF FF FF
					39 00 00 40 00 00 09 91 03 30 24 00 00 00 00 00
					39 00 00 40 00 00 04 FF 5A A5 29
					39 00 00 40 00 00 09 82 74 2C 2A 2A 28 28 26 26
					39 00 00 40 00 00 09 83 24 24 22 22 20 20 1E 1E
					39 00 00 40 00 00 09 84 1C 1C 1A 1A 18 18 18 18
					39 00 00 40 00 00 07 85 18 18 18 18 18 18
					39 00 00 00 00 00 04 FF 5A A5 00
					/* 60hz 3 pulse */
					39 00 00 40 00 00 04 FF 5A A5 00
					15 00 00 40 00 00 02 60 00
					15 00 00 40 00 00 02 7D 00
					39 00 00 40 00 00 04 FF 5A A5 2D
					39 00 00 40 00 00 03 83 01 00
					15 00 00 40 00 00 02 F2 01
					39 00 00 00 00 00 04 FF 5A A5 00

					05 00 00 00 78 00 01 11
					05 00 00 00 14 00 01 29
				];
			};
			timing@sdc_fhd_144 {
				#include "dsi-panel-AA601-P-7-A0020-common.dtsi"
				#include "dsi-panel-AA601-P-7-A0020-loading-effect.dtsi"
				qcom,mdss-mdp-transfer-time-us = <6100>;
				qcom,mdss-dsi-panel-jitter = <0x4 0x1>;
				qcom,mdss-dsc-version = <0x12>;
				qcom,mdss-dsi-timing-default;
				qcom,mdss-dsi-panel-framerate = <144>;
				qcom,mdss-dsi-panel-clockrate = <1363200000>;
				qcom,mdss-dsi-panel-width = <1272>;
				qcom,mdss-dsi-panel-height = <2772>;

				qcom,mdss-dsi-h-front-porch = <26>;
				qcom,mdss-dsi-h-back-porch = <26>;
				qcom,mdss-dsi-h-pulse-width = <2>;
				qcom,mdss-dsi-v-back-porch = <42>;
				qcom,mdss-dsi-v-front-porch = <58>;
				qcom,mdss-dsi-v-pulse-width = <2>;
				qcom,mdss-dsi-h-sync-pulse = <0>;

				oplus,ofp-need-to-sync-data-in-aod-unlocking;
				oplus,ofp-aod-off-insert-black-frame = <1>;
				oplus,ofp-aod-off-black-frame-total-time = <42>;
				oplus,ofp-need-to-separate-backlight;
				oplus,ofp-backlight-on-period = <1>;

				qcom,mdss-dsi-timing-switch-command = [
					39 00 00 40 00 00 04 FF 5A A5 00
					15 00 00 40 00 00 02 60 04 //144hz 3 pulse
					15 00 00 40 00 00 02 7D 01
					39 00 00 40 00 00 04 FF 5A A5 2D
					39 00 00 40 00 00 03 87 00 00
					39 00 00 00 00 00 04 FF 5A A5 00
				];

				qcom,mdss-dsi-timing-switch-compensation-command = [
					39 00 00 40 00 00 04 FF 5A A5 08 //Page 8
					15 00 00 40 00 00 02 98 02 //Disable CMD FIFO reset
					39 00 00 40 00 00 04 FF 5A A5 4F //Page 4F
					15 00 00 40 00 00 02 81 06
					15 00 00 40 00 00 02 88 78 //MFSC Start
					//D3G
					39 00 00 40 00 00 04 FF 5A A5 24
					39 00 00 40 00 00 06 C9 00 00 00 10 00
					39 00 00 40 00 00 04 FE 30 00 50
					39 00 00 40 00 00 06 CA 00 70 00 B0 01
					39 00 00 40 00 00 04 FE 00 01 30
					39 00 00 40 00 00 06 CB 01 73 01 AD 01
					39 00 00 40 00 00 04 FE F0 02 70
					39 00 00 40 00 00 06 CC 02 F0 03 50 03
					39 00 00 40 00 00 04 FE F0 04 70
					39 00 00 40 00 00 06 CD 04 F0 06 E0 08
					39 00 00 40 00 00 04 FE F0 0A 00
					39 00 00 40 00 00 06 CE 0B A0 0C D0 0D
					39 00 00 40 00 00 04 FE C0 0F F0
					39 00 00 40 00 00 04 FF 5A A5 4F //Page 4F
					15 00 00 40 00 00 02 8A 78 //MFSC Start
					//Mode control
					39 00 00 40 00 00 04 FF 5A A5 00 //Page 0
					15 00 00 40 00 00 02 60 04 //144HZ
					//D3G
					39 00 00 40 00 00 04 FF 5A A5 24
					39 00 00 40 00 00 06 C9 00 00 00 10 00
					39 00 00 40 00 00 04 FE 30 00 50
					39 00 00 40 00 00 06 CA 00 70 00 B0 00
					39 00 00 40 00 00 04 FE F0 01 30
					39 00 00 40 00 00 06 CB 01 70 01 B0 01
					39 00 00 40 00 00 04 FE F0 02 70
					39 00 00 40 00 00 06 CC 02 F0 03 70 03
					39 00 00 40 00 00 04 FE F0 04 70
					39 00 00 40 00 00 06 CD 04 F0 06 F0 08
					39 00 00 40 00 00 04 FE F0 0A 00
					39 00 00 40 00 00 06 CE 0B A0 0C D0 0E
					39 00 00 40 00 00 04 FE 10 0F F0
					//1 Gamma mode
					39 00 00 40 00 00 04 FF 5A A5 23
					15 00 00 40 00 00 02 CA 00
					15 00 00 40 00 00 02 CE 00
					//1 Gamma mode group
					39 00 00 40 00 00 04 FF 5A A5 24
					15 00 00 40 00 00 02 8D 42
					15 00 00 40 00 00 02 8E 74
					15 00 00 40 00 00 02 8F 50
					15 00 00 40 00 00 02 90 64
					//Normal DMR
					39 00 00 40 00 00 04 FF 5A A5 53
					15 00 00 40 00 00 02 F0 01
					15 00 00 40 00 00 02 00 00
					15 00 00 40 00 00 02 00 00
					15 00 00 40 00 00 02 00 00
					15 00 00 40 00 00 02 00 00
					15 00 00 40 00 00 02 00 00
					15 00 00 40 00 00 02 00 00
					15 00 00 40 00 00 02 00 00
					15 00 00 40 00 00 02 00 00
					39 00 00 40 00 00 04 FF 5A A5 63
					39 00 00 40 00 00 06 F1 20 20 20 20 20
					39 00 00 40 00 00 06 FE 20 00 00 00 00
					39 00 00 40 00 00 06 FE 00 00 00 00 00
					15 00 00 40 00 00 02 FE 00
					15 00 00 40 00 00 02 00 00
					15 00 00 40 00 00 02 00 00
					15 00 00 40 00 00 02 00 00
					15 00 00 40 00 00 02 00 00
					15 00 00 40 00 00 02 00 00
					39 00 00 40 00 00 06 F2 00 00 00 00 00
					39 00 00 40 00 00 06 FE 00 00 00 00 00
					39 00 00 40 00 00 06 FE 00 00 00 00 00
					15 00 00 40 00 00 02 FE 00
					15 00 00 40 00 00 02 00 00
					15 00 00 40 00 00 02 00 00
					15 00 00 40 00 00 02 00 00
					15 00 00 40 00 00 02 00 00
					15 00 00 40 00 00 02 00 00
					39 00 00 40 00 00 06 F3 00 00 00 00 00
					39 00 00 40 00 00 06 FE 00 20 20 20 20
					39 00 00 40 00 00 06 FE 00 00 00 00 00
					15 00 00 40 00 00 02 FE 00
					15 00 00 40 00 00 02 00 00
					15 00 00 40 00 00 02 00 00
					15 00 00 40 00 00 02 00 00
					15 00 00 40 00 00 02 00 00
					15 00 00 40 00 00 02 00 00
					39 00 00 40 00 00 06 F4 00 00 00 00 00
					39 00 00 40 00 00 06 FE 00 F0 F0 F0 F0
					39 00 00 40 00 00 06 FE 00 00 00 00 00
					15 00 00 40 00 00 02 FE 00
					15 00 00 40 00 00 02 00 00
					15 00 00 40 00 00 02 00 00
					15 00 00 40 00 00 02 00 00
					15 00 00 40 00 00 02 00 00
					15 00 00 40 00 00 02 00 00
					15 00 00 40 00 00 02 00 00
					15 00 00 40 00 00 02 00 00
					15 00 00 40 00 00 02 00 00
					39 00 00 40 00 00 04 FF 5A A5 53
					15 00 00 40 00 00 02 F0 00
					39 00 00 40 00 00 04 FF 5A A5 08 //Page 8
					15 00 00 40 00 00 02 98 A6 //Enable CMD FIFO reset
					39 00 00 40 00 00 04 FF 5A A5 00 //Page 0
					15 00 00 40 00 00 02 00 00 //Dummy write
					39 00 00 40 00 00 04 FF 5A A5 4F //Page 4F
					15 00 00 40 00 00 02 8B 78 //MFSC All done
					39 00 00 00 00 00 04 FF 5A A5 00
					/* wait for te and blocking one frame */
					39 00 00 20 00 00 04 FF 5A A5 00
				];

				qcom,mdss-dsi-on-command = [
					39 00 00 40 00 00 04 FF 5A A5 13
					15 00 00 40 00 00 02 F9 4C //HOLE OFF
					39 00 00 40 00 00 04 FF 5A A5 17
					15 00 00 40 00 00 02 A0 0E //RCN OFF
					//SPR in AP Start
					39 00 00 40 00 00 04 FF 5A A5 07
					15 00 00 40 00 00 02 8A 01
					39 00 00 40 00 00 03 8B 21 E0
					39 00 00 40 00 00 64 80 00 00 00 00 00 12 00 00 AB 30 80 0A D4 04 F8 00 16 02 7C 02 7C 02 00 02 59 00 20 02 2E 00 08 00 0D 04 F4 03 ED 18 00 10 F0 07 10 20 00 06 0F 0F 33 0E 1C 2A 38 46 54 62 69 70 77 79 7B 7D 7E 02 02 22 00 2A 40 2A BE 3A FC 3A FA 3A F8 3B 38 3B 78 3B B6 4B B6 4B F4 4B F4 6C 34 84 74 00 00 00 00 00 00
					39 00 00 40 00 00 64 81 00 00 00 00 00 12 00 00 AB 21 00 0A D4 04 F8 00 16 02 7C 02 7C 01 55 01 D7 00 0A 01 2D 00 35 00 0D 04 F4 16 3B 08 00 0C 00 07 10 20 00 06 0F 0F 33 0E 1C 2A 38 46 54 62 69 70 77 79 7B 7D 7E 00 82 11 40 19 C0 22 3E 32 7C 3A BA 3A F8 3B 38 3B 38 3B 76 4B 76 4B 74 4B 74 5B B4 73 F4 01 00 00 00 00 00
					39 00 00 40 00 00 04 FF 5A A5 07
					15 00 00 40 00 00 02 91 03 //Ycrcb
					39 00 00 40 00 00 04 FF 5A A5 14
					15 00 00 40 00 00 02 82 01 //SPR IN AP  ON
					39 00 00 40 00 00 04 FF 5A A5 14
					15 00 00 40 00 00 02 80 00 //DDIC SPR OFF
					//SPR in AP END
					39 00 00 40 00 00 04 FF 5A A5 4F
					15 00 00 40 00 00 02 81 06 //CMDQ SETTING
					39 00 00 40 00 00 04 FF 5A A5 08
					15 00 00 40 00 00 02 C8 62 //OTP don’t reload
					39 00 00 40 00 00 04 FF 5A A5 21
					15 00 00 40 00 00 02 A4 38 //Flash reload
					39 00 00 40 00 00 04 FF 5A A5 23
					15 00 00 40 00 00 02 85 15 //BC reload by OTP
					39 00 00 40 00 00 04 FF 5A A5 01
					15 00 00 40 00 00 02 FB 08 //Multi TE
					39 00 00 40 00 00 04 FF 5A A5 06
					15 00 00 40 00 00 02 A0 00 //ESD fixed
					15 00 00 40 00 00 02 C6 01 //1bit ESD check
					39 00 00 40 00 00 04 FF 5A A5 08
					15 00 00 40 00 00 02 D2 05
					15 00 00 40 00 00 02 D3 01
					/* FFC Setting */
					39 00 00 40 00 00 04 FF 5A A5 22
					39 00 00 40 00 00 08 D8 01 00 11 10 3C 18 18 //120HZ
					39 00 00 40 00 00 08 D9 00 FC 11 10 30 18 18 //144/165Hz
					39 00 00 40 00 00 0A DC 84 94 BB 00 20 C4 A1 CC 10
					15 00 00 40 00 00 02 DD 01
					15 00 00 40 00 00 02 DE F1
					15 00 00 40 00 00 02 DF 80
					39 00 00 40 00 00 07 E0 02 00 5F 21 00 28
					39 00 00 40 00 00 04 FF 5A A5 00
					15 00 00 40 00 00 02 7D 00
					39 00 00 40 00 00 04 FF 5A A5 00
					15 00 00 40 00 00 02 5E 01
					15 00 00 40 00 00 02 60 00
					15 00 00 40 00 00 02 61 07
					15 00 00 40 00 00 02 6D 01
					05 00 00 40 00 00 01 35
					15 00 00 00 00 00 02 53 20
					39 00 00 40 00 00 04 FF 5A A5 2D
					39 00 00 40 00 00 04 EC 01 FF 00 //SF en
					39 00 00 40 00 00 03 94 F5 00 // 144Hz SF mode2  165hz SF mode4
					39 00 00 00 00 00 04 FF 5A A5 00

					/* SC6027 */
					39 00 00 40 00 00 04 FF 5A A5 20
					15 00 00 40 00 00 02 C8 00
					15 00 00 40 00 00 02 C7 00
					39 00 00 40 00 00 04 FF 5A A5 00
					39 00 00 40 00 00 05 94 00 D0 00 00
					39 00 00 40 00 00 04 FF 5A A5 1F
					15 00 00 40 00 00 02 87 09
					15 00 00 40 00 00 02 88 34
					39 00 00 40 00 00 05 89 41 00 C4 01
					39 00 00 40 00 00 03 8A 8C 14
					39 00 00 40 00 00 05 8C 80 07 00 40
					15 00 00 40 00 00 02 8E 10
					15 00 00 40 00 00 02 95 00
					39 00 00 40 00 00 05 96 15 35 55 01
					39 00 00 40 00 00 19 83 00 0B 0A 0C 02 0F FF FF 0C 02 FF FF 00 FF 00 0B 00 FF FF FF FF FF FF FF
					39 00 00 40 00 00 19 8F 03 30 8C 19 0F 18 00 00 19 0F 00 00 00 00 02 30 02 00 00 00 00 00 00 00
					39 00 00 40 00 00 09 85 00 0B 0A FF FF FF FF FF
					39 00 00 40 00 00 09 91 03 30 24 00 00 00 00 00
					39 00 00 40 00 00 04 FF 5A A5 29
					39 00 00 40 00 00 09 82 74 2C 2A 2A 28 28 26 26
					39 00 00 40 00 00 09 83 24 24 22 22 20 20 1E 1E
					39 00 00 40 00 00 09 84 1C 1C 1A 1A 18 18 18 18
					39 00 00 40 00 00 07 85 18 18 18 18 18 18
					39 00 00 00 00 00 04 FF 5A A5 00
					/* 144hz 3 pulse */
					39 00 00 40 00 00 04 FF 5A A5 00
					15 00 00 40 00 00 02 60 04 //144hz 3 pulse
					15 00 00 40 00 00 02 7D 01
					39 00 00 40 00 00 04 FF 5A A5 2D
					39 00 00 40 00 00 03 87 00 00
					39 00 00 00 00 00 04 FF 5A A5 00

					05 00 00 00 78 00 01 11
					05 00 00 00 14 00 01 29
				];
			};
			timing@sdc_fhd_165 {
				#include "dsi-panel-AA601-P-7-A0020-common.dtsi"
				#include "dsi-panel-AA601-P-7-A0020-loading-effect.dtsi"
				qcom,mdss-mdp-transfer-time-us = <5200>;
				qcom,mdss-dsi-panel-jitter = <0x4 0x1>;
				qcom,mdss-dsc-version = <0x12>;
				qcom,mdss-dsi-timing-default;
				qcom,mdss-dsi-panel-framerate = <165>;
				qcom,mdss-dsi-panel-clockrate = <1363200000>;
				qcom,mdss-dsi-panel-width = <1272>;
				qcom,mdss-dsi-panel-height = <2772>;

				qcom,mdss-dsi-h-front-porch = <26>;
				qcom,mdss-dsi-h-back-porch = <26>;
				qcom,mdss-dsi-h-pulse-width = <2>;
				qcom,mdss-dsi-v-back-porch = <42>;
				qcom,mdss-dsi-v-front-porch = <58>;
				qcom,mdss-dsi-v-pulse-width = <2>;
				qcom,mdss-dsi-h-sync-pulse = <0>;

				oplus,ofp-need-to-sync-data-in-aod-unlocking;
				oplus,ofp-aod-off-insert-black-frame = <1>;
				oplus,ofp-aod-off-black-frame-total-time = <42>;
				oplus,ofp-need-to-separate-backlight;
				oplus,ofp-backlight-on-period = <1>;

				qcom,mdss-dsi-timing-switch-compensation-command = [
					39 00 00 40 00 00 04 FF 5A A5 08 //Page 8
					15 00 00 40 00 00 02 98 02 //Disable CMD FIFO reset
					39 00 00 40 00 00 04 FF 5A A5 4F //Page 4F
					15 00 00 40 00 00 02 81 06
					15 00 00 40 00 00 02 88 78 //MFSC Start
					//D3G
					39 00 00 40 00 00 04 FF 5A A5 24
					39 00 00 40 00 00 06 C9 00 00 00 10 00
					39 00 00 40 00 00 04 FE 30 00 50
					39 00 00 40 00 00 06 CA 00 70 00 B0 00
					39 00 00 40 00 00 04 FE E0 01 30
					39 00 00 40 00 00 06 CB 01 60 01 B9 01
					39 00 00 40 00 00 04 FE F0 02 70
					39 00 00 40 00 00 06 CC 02 F0 03 70 03
					39 00 00 40 00 00 04 FE F0 04 70
					39 00 00 40 00 00 06 CD 04 F0 06 FB 08
					39 00 00 40 00 00 04 FE F0 0A 00
					39 00 00 40 00 00 06 CE 0B A0 0C D0 0E
					39 00 00 40 00 00 04 FE 40 0F F0
					39 00 00 40 00 00 04 FF 5A A5 4F //Page 4F
					15 00 00 40 00 00 02 8A 78 //MFSC Start
					//Mode control
					39 00 00 40 00 00 04 FF 5A A5 00 //Page 0
					15 00 00 40 00 00 02 60 06 //165HZ
					15 00 00 40 00 00 02 7D 01
					//D3G
					39 00 00 40 00 00 04 FF 5A A5 24
					39 00 00 40 00 00 06 C9 00 00 00 10 00
					39 00 00 40 00 00 04 FE 30 00 50
					39 00 00 40 00 00 06 CA 00 70 00 B0 00
					39 00 00 40 00 00 04 FE F0 01 30
					39 00 00 40 00 00 06 CB 01 70 01 B0 01
					39 00 00 40 00 00 04 FE F0 02 70
					39 00 00 40 00 00 06 CC 02 F0 03 70 03
					39 00 00 40 00 00 04 FE F0 04 70
					39 00 00 40 00 00 06 CD 04 F0 06 F0 08
					39 00 00 40 00 00 04 FE F0 0A 00
					39 00 00 40 00 00 06 CE 0B A0 0C D0 0E
					39 00 00 40 00 00 04 FE 10 0F F0
					//1 Gamma mode
					39 00 00 40 00 00 04 FF 5A A5 23
					15 00 00 40 00 00 02 CA 00
					15 00 00 40 00 00 02 CE 00
					//1 Gamma mode group
					39 00 00 40 00 00 04 FF 5A A5 24
					15 00 00 40 00 00 02 8D 42
					15 00 00 40 00 00 02 8E 74
					15 00 00 40 00 00 02 8F 50
					15 00 00 40 00 00 02 90 64
					//165hz DMR
					39 00 00 40 00 00 04 FF 5A A5 53
					15 00 00 40 00 00 02 F0 01
					15 00 00 40 00 00 02 00 00
					15 00 00 40 00 00 02 00 00
					15 00 00 40 00 00 02 00 00
					15 00 00 40 00 00 02 00 00
					15 00 00 40 00 00 02 00 00
					15 00 00 40 00 00 02 00 00
					15 00 00 40 00 00 02 00 00
					15 00 00 40 00 00 02 00 00
					39 00 00 40 00 00 04 FF 5A A5 63
					39 00 00 40 00 00 06 F1 20 20 20 20 20
					39 00 00 40 00 00 06 FE 20 00 00 00 00
					39 00 00 40 00 00 06 FE 00 00 00 00 00
					15 00 00 40 00 00 02 FE 00
					15 00 00 40 00 00 02 00 00
					15 00 00 40 00 00 02 00 00
					15 00 00 40 00 00 02 00 00
					15 00 00 40 00 00 02 00 00
					15 00 00 40 00 00 02 00 00
					39 00 00 40 00 00 06 F2 00 00 00 00 00
					39 00 00 40 00 00 06 FE 00 20 20 20 20
					39 00 00 40 00 00 06 FE 00 00 00 00 00
					15 00 00 40 00 00 02 FE 00
					15 00 00 40 00 00 02 00 00
					15 00 00 40 00 00 02 00 00
					15 00 00 40 00 00 02 00 00
					15 00 00 40 00 00 02 00 00
					15 00 00 40 00 00 02 00 00
					39 00 00 40 00 00 06 F3 00 00 00 00 00
					39 00 00 40 00 00 06 FE 00 00 00 00 00
					39 00 00 40 00 00 06 FE 00 00 00 00 00
					15 00 00 40 00 00 02 FE 00
					15 00 00 40 00 00 02 00 00
					15 00 00 40 00 00 02 00 00
					15 00 00 40 00 00 02 00 00
					15 00 00 40 00 00 02 00 00
					15 00 00 40 00 00 02 00 00
					39 00 00 40 00 00 06 F4 00 00 00 00 00
					39 00 00 40 00 00 06 FE 00 F0 F0 F0 F0
					39 00 00 40 00 00 06 FE 00 00 00 00 00
					15 00 00 40 00 00 02 FE 00
					15 00 00 40 00 00 02 00 00
					15 00 00 40 00 00 02 00 00
					15 00 00 40 00 00 02 00 00
					15 00 00 40 00 00 02 00 00
					15 00 00 40 00 00 02 00 00
					15 00 00 40 00 00 02 00 00
					15 00 00 40 00 00 02 00 00
					15 00 00 40 00 00 02 00 00
					39 00 00 40 00 00 04 FF 5A A5 53
					15 00 00 40 00 00 02 F0 00
					39 00 00 40 00 00 04 FF 5A A5 08 //Page 8
					15 00 00 40 00 00 02 98 A6 //Enable CMD FIFO reset
					39 00 00 40 00 00 04 FF 5A A5 00 //Page 0
					15 00 00 40 00 00 02 00 00 //Dummy write
					39 00 00 40 00 00 04 FF 5A A5 4F //Page 4F
					15 00 00 40 00 00 02 8B 78 //MFSC All done
					39 00 00 00 00 00 04 FF 5A A5 00
					/* wait for te and blocking one frame */
					39 00 00 20 00 00 04 FF 5A A5 00
				];
				qcom,mdss-dsi-on-command = [
					39 00 00 40 00 00 04 FF 5A A5 13
					15 00 00 40 00 00 02 F9 4C //HOLE OFF
					39 00 00 40 00 00 04 FF 5A A5 17
					15 00 00 40 00 00 02 A0 0E //RCN OFF
					//SPR in AP Start
					39 00 00 40 00 00 04 FF 5A A5 07
					15 00 00 40 00 00 02 8A 01
					39 00 00 40 00 00 03 8B 21 E0
					39 00 00 40 00 00 64 80 00 00 00 00 00 12 00 00 AB 30 80 0A D4 04 F8 00 16 02 7C 02 7C 02 00 02 59 00 20 02 2E 00 08 00 0D 04 F4 03 ED 18 00 10 F0 07 10 20 00 06 0F 0F 33 0E 1C 2A 38 46 54 62 69 70 77 79 7B 7D 7E 02 02 22 00 2A 40 2A BE 3A FC 3A FA 3A F8 3B 38 3B 78 3B B6 4B B6 4B F4 4B F4 6C 34 84 74 00 00 00 00 00 00
					39 00 00 40 00 00 64 81 00 00 00 00 00 12 00 00 AB 21 00 0A D4 04 F8 00 16 02 7C 02 7C 01 55 01 D7 00 0A 01 2D 00 35 00 0D 04 F4 16 3B 08 00 0C 00 07 10 20 00 06 0F 0F 33 0E 1C 2A 38 46 54 62 69 70 77 79 7B 7D 7E 00 82 11 40 19 C0 22 3E 32 7C 3A BA 3A F8 3B 38 3B 38 3B 76 4B 76 4B 74 4B 74 5B B4 73 F4 01 00 00 00 00 00
					39 00 00 40 00 00 04 FF 5A A5 07
					15 00 00 40 00 00 02 91 03 //Ycrcb
					39 00 00 40 00 00 04 FF 5A A5 14
					15 00 00 40 00 00 02 82 01 //SPR IN AP  ON
					39 00 00 40 00 00 04 FF 5A A5 14
					15 00 00 40 00 00 02 80 00 //DDIC SPR OFF
					//SPR in AP END
					39 00 00 40 00 00 04 FF 5A A5 4F
					15 00 00 40 00 00 02 81 06 //CMDQ SETTING
					39 00 00 40 00 00 04 FF 5A A5 08
					15 00 00 40 00 00 02 C8 62 //OTP don’t reload
					39 00 00 40 00 00 04 FF 5A A5 21
					15 00 00 40 00 00 02 A4 38 //Flash reload
					39 00 00 40 00 00 04 FF 5A A5 23
					15 00 00 40 00 00 02 85 15 //BC reload by OTP
					39 00 00 40 00 00 04 FF 5A A5 01
					15 00 00 40 00 00 02 FB 08 //Multi TE
					39 00 00 40 00 00 04 FF 5A A5 06
					15 00 00 40 00 00 02 A0 00 //ESD fixed
					15 00 00 40 00 00 02 C6 01 //1bit ESD check
					39 00 00 40 00 00 04 FF 5A A5 08
					15 00 00 40 00 00 02 D2 05
					15 00 00 40 00 00 02 D3 01
					/* FFC Setting */
					39 00 00 40 00 00 04 FF 5A A5 22
					39 00 00 40 00 00 08 D8 01 00 11 10 3C 18 18 //120HZ
					39 00 00 40 00 00 08 D9 00 FC 11 10 30 18 18 //144/165Hz
					39 00 00 40 00 00 0A DC 84 94 BB 00 20 C4 A1 CC 10
					15 00 00 40 00 00 02 DD 01
					15 00 00 40 00 00 02 DE F1
					15 00 00 40 00 00 02 DF 80
					39 00 00 40 00 00 07 E0 02 00 5F 21 00 28
					39 00 00 40 00 00 04 FF 5A A5 00
					15 00 00 40 00 00 02 7D 00
					39 00 00 40 00 00 04 FF 5A A5 00
					15 00 00 40 00 00 02 5E 01
					15 00 00 40 00 00 02 60 00
					15 00 00 40 00 00 02 61 07
					15 00 00 40 00 00 02 6D 01
					05 00 00 40 00 00 01 35
					15 00 00 00 00 00 02 53 20
					39 00 00 40 00 00 04 FF 5A A5 2D
					39 00 00 40 00 00 04 EC 01 FF 00 //SF en
					39 00 00 40 00 00 03 94 F5 00 // 144Hz SF mode2  165hz SF mode4
					39 00 00 00 00 00 04 FF 5A A5 00

					/* SC6027 */
					39 00 00 40 00 00 04 FF 5A A5 20
					15 00 00 40 00 00 02 C8 00
					15 00 00 40 00 00 02 C7 00
					39 00 00 40 00 00 04 FF 5A A5 00
					39 00 00 40 00 00 05 94 00 D0 00 00
					39 00 00 40 00 00 04 FF 5A A5 1F
					15 00 00 40 00 00 02 87 09
					15 00 00 40 00 00 02 88 34
					39 00 00 40 00 00 05 89 41 00 C4 01
					39 00 00 40 00 00 03 8A 8C 14
					39 00 00 40 00 00 05 8C 80 07 00 40
					15 00 00 40 00 00 02 8E 10
					15 00 00 40 00 00 02 95 00
					39 00 00 40 00 00 05 96 15 35 55 01
					39 00 00 40 00 00 19 83 00 0B 0A 0C 02 0F FF FF 0C 02 FF FF 00 FF 00 0B 00 FF FF FF FF FF FF FF
					39 00 00 40 00 00 19 8F 03 30 8C 19 0F 18 00 00 19 0F 00 00 00 00 02 30 02 00 00 00 00 00 00 00
					39 00 00 40 00 00 09 85 00 0B 0A FF FF FF FF FF
					39 00 00 40 00 00 09 91 03 30 24 00 00 00 00 00
					39 00 00 40 00 00 04 FF 5A A5 29
					39 00 00 40 00 00 09 82 74 2C 2A 2A 28 28 26 26
					39 00 00 40 00 00 09 83 24 24 22 22 20 20 1E 1E
					39 00 00 40 00 00 09 84 1C 1C 1A 1A 18 18 18 18
					39 00 00 40 00 00 07 85 18 18 18 18 18 18
					39 00 00 00 00 00 04 FF 5A A5 00
					/* 165hz 3 pulse */
					39 00 00 40 00 00 04 FF 5A A5 00
					15 00 00 40 00 00 02 60 06 //165hz 3 pulse
					15 00 00 40 00 00 02 7D 01
					39 00 00 40 00 00 04 FF 5A A5 2D
					39 00 00 40 00 00 03 89 00 00
					39 00 00 00 00 00 04 FF 5A A5 00

					05 00 00 00 78 00 01 11
					05 00 00 00 14 00 01 29
				];
			};
			timing@oplus_fhd_120 {
				#include "dsi-panel-AA601-P-7-A0020-common.dtsi"
				#include "dsi-panel-AA601-P-7-A0020-loading-effect.dtsi"
				qcom,mdss-mdp-transfer-time-us = <6900>;
				qcom,mdss-dsi-panel-jitter = <0x4 0x1>;
				qcom,mdss-dsc-version = <0x12>;
				qcom,mdss-dsi-timing-default;
				qcom,mdss-dsi-panel-framerate = <120>;
				qcom,mdss-dsi-panel-clockrate = <1112600000>;
				qcom,mdss-dsi-panel-width = <1272>;
				qcom,mdss-dsi-panel-height = <2772>;

				qcom,mdss-dsi-h-front-porch = <26>;
				qcom,mdss-dsi-h-back-porch = <26>;
				qcom,mdss-dsi-h-pulse-width = <2>;
				qcom,mdss-dsi-v-back-porch = <42>;
				qcom,mdss-dsi-v-front-porch = <58>;
				qcom,mdss-dsi-v-pulse-width = <2>;
				qcom,mdss-dsi-h-sync-pulse = <0>;

				oplus,ofp-need-to-sync-data-in-aod-unlocking;
				oplus,ofp-aod-off-insert-black-frame = <1>;
				oplus,ofp-aod-off-black-frame-total-time = <42>;
				oplus,ofp-need-to-separate-backlight;
				oplus,ofp-backlight-on-period = <1>;

				qcom,mdss-dsi-timing-switch-command = [
					39 00 00 40 00 00 04 FF 5A A5 00
					15 00 00 40 00 00 02 60 00 //120hz 3 pulse
					15 00 00 40 00 00 02 7D 00
					39 00 00 40 00 00 04 FF 5A A5 2D
					39 00 00 40 00 00 03 83 00 00
					15 00 00 40 00 00 02 F2 00
					39 00 00 00 00 00 04 FF 5A A5 00
				];
				qcom,mdss-dsi-on-command = [
					39 00 00 40 00 00 04 FF 5A A5 13
					15 00 00 40 00 00 02 F9 4C //HOLE OFF
					39 00 00 40 00 00 04 FF 5A A5 17
					15 00 00 40 00 00 02 A0 0E //RCN OFF
					//SPR in AP Start
					39 00 00 40 00 00 04 FF 5A A5 07
					15 00 00 40 00 00 02 8A 01
					39 00 00 40 00 00 03 8B 21 E0
					39 00 00 40 00 00 64 80 00 00 00 00 00 12 00 00 AB 30 80 0A D4 04 F8 00 16 02 7C 02 7C 02 00 02 59 00 20 02 2E 00 08 00 0D 04 F4 03 ED 18 00 10 F0 07 10 20 00 06 0F 0F 33 0E 1C 2A 38 46 54 62 69 70 77 79 7B 7D 7E 02 02 22 00 2A 40 2A BE 3A FC 3A FA 3A F8 3B 38 3B 78 3B B6 4B B6 4B F4 4B F4 6C 34 84 74 00 00 00 00 00 00
					39 00 00 40 00 00 64 81 00 00 00 00 00 12 00 00 AB 21 00 0A D4 04 F8 00 16 02 7C 02 7C 01 55 01 D7 00 0A 01 2D 00 35 00 0D 04 F4 16 3B 08 00 0C 00 07 10 20 00 06 0F 0F 33 0E 1C 2A 38 46 54 62 69 70 77 79 7B 7D 7E 00 82 11 40 19 C0 22 3E 32 7C 3A BA 3A F8 3B 38 3B 38 3B 76 4B 76 4B 74 4B 74 5B B4 73 F4 01 00 00 00 00 00
					39 00 00 40 00 00 04 FF 5A A5 07
					15 00 00 40 00 00 02 91 03 //Ycrcb
					39 00 00 40 00 00 04 FF 5A A5 14
					15 00 00 40 00 00 02 82 01 //SPR IN AP  ON
					39 00 00 40 00 00 04 FF 5A A5 14
					15 00 00 40 00 00 02 80 00 //DDIC SPR OFF
					//SPR in AP END
					39 00 00 40 00 00 04 FF 5A A5 4F
					15 00 00 40 00 00 02 81 06 //CMDQ SETTING
					39 00 00 40 00 00 04 FF 5A A5 08
					15 00 00 40 00 00 02 C8 62 //OTP don’t reload
					39 00 00 40 00 00 04 FF 5A A5 21
					15 00 00 40 00 00 02 A4 38 //Flash reload
					39 00 00 40 00 00 04 FF 5A A5 23
					15 00 00 40 00 00 02 85 15 //BC reload by OTP
					39 00 00 40 00 00 04 FF 5A A5 01
					15 00 00 40 00 00 02 FB 08 //Multi TE
					39 00 00 40 00 00 04 FF 5A A5 06
					15 00 00 40 00 00 02 A0 00 //ESD fixed
					15 00 00 40 00 00 02 C6 01 //1bit ESD check
					39 00 00 40 00 00 04 FF 5A A5 08
					15 00 00 40 00 00 02 D2 05
					15 00 00 40 00 00 02 D3 01
					/* FFC Setting */
					39 00 00 40 00 00 04 FF 5A A5 22
					39 00 00 40 00 00 08 D8 01 00 11 10 3C 18 18 //120HZ
					39 00 00 40 00 00 08 D9 00 FC 11 10 30 18 18 //144/165Hz
					39 00 00 40 00 00 0A DC 84 94 BB 00 20 C4 A1 CC 10
					15 00 00 40 00 00 02 DD 01
					15 00 00 40 00 00 02 DE F1
					15 00 00 40 00 00 02 DF 80
					39 00 00 40 00 00 07 E0 02 00 5F 21 00 28
					39 00 00 40 00 00 04 FF 5A A5 00
					15 00 00 40 00 00 02 7D 00
					39 00 00 40 00 00 04 FF 5A A5 00
					15 00 00 40 00 00 02 5E 01
					15 00 00 40 00 00 02 60 00
					15 00 00 40 00 00 02 61 07
					15 00 00 40 00 00 02 6D 01
					05 00 00 40 00 00 01 35
					15 00 00 00 00 00 02 53 20
					39 00 00 40 00 00 04 FF 5A A5 2D
					39 00 00 40 00 00 04 EC 01 FF 00 //SF en
					39 00 00 40 00 00 03 94 F5 00 // 144Hz SF mode2  165hz SF mode4
					39 00 00 00 00 00 04 FF 5A A5 00

					/* SC6027 */
					39 00 00 40 00 00 04 FF 5A A5 20
					15 00 00 40 00 00 02 C8 00
					15 00 00 40 00 00 02 C7 00
					39 00 00 40 00 00 04 FF 5A A5 00
					39 00 00 40 00 00 05 94 00 D0 00 00
					39 00 00 40 00 00 04 FF 5A A5 1F
					15 00 00 40 00 00 02 87 09
					15 00 00 40 00 00 02 88 34
					39 00 00 40 00 00 05 89 41 00 C4 01
					39 00 00 40 00 00 03 8A 8C 14
					39 00 00 40 00 00 05 8C 80 07 00 40
					15 00 00 40 00 00 02 8E 10
					15 00 00 40 00 00 02 95 00
					39 00 00 40 00 00 05 96 15 35 55 01
					39 00 00 40 00 00 19 83 00 0B 0A 0C 02 0F FF FF 0C 02 FF FF 00 FF 00 0B 00 FF FF FF FF FF FF FF
					39 00 00 40 00 00 19 8F 03 30 8C 19 0F 18 00 00 19 0F 00 00 00 00 02 30 02 00 00 00 00 00 00 00
					39 00 00 40 00 00 09 85 00 0B 0A FF FF FF FF FF
					39 00 00 40 00 00 09 91 03 30 24 00 00 00 00 00
					39 00 00 40 00 00 04 FF 5A A5 29
					39 00 00 40 00 00 09 82 74 2C 2A 2A 28 28 26 26
					39 00 00 40 00 00 09 83 24 24 22 22 20 20 1E 1E
					39 00 00 40 00 00 09 84 1C 1C 1A 1A 18 18 18 18
					39 00 00 40 00 00 07 85 18 18 18 18 18 18
					39 00 00 00 00 00 04 FF 5A A5 00
					/* 120hz 3 pulse */
					39 00 00 40 00 00 04 FF 5A A5 00
					15 00 00 40 00 00 02 60 00 //120hz 3 pulse
					15 00 00 40 00 00 02 7D 00
					39 00 00 40 00 00 04 FF 5A A5 2D
					39 00 00 40 00 00 03 83 00 00
					15 00 00 40 00 00 02 F2 00
					39 00 00 00 00 00 04 FF 5A A5 00

					05 00 00 00 78 00 01 11
					05 00 00 00 14 00 01 29
				];
			};
		};
	};
};

&soc {
	dsi_panel_AA601_P_7_A0020_dsc_cmd {
		qcom,dsi-display-active;
	};
};

&dsi_panel_AA601_P_7_A0020_dsc_cmd {
	qcom,panel-supply-entries = <&oplus_dsi_panel_custom_pwr_supply>;
	qcom,platform-te-gpio = <&tlmm 86 0>;
	qcom,platform-reset-gpio = <&tlmm 171 0>;
	/* OLED_PMIC_RST */
	oplus,panel-gpio1 = <&pmk8850_gpios 1 0>;
	/* VDDR_SM_1P5_EN */
	oplus,panel-gpio2 = <&pmh0101_gpios 4 0>;

	oplus,panel-reset-position = <0x02>;
	oplus,panel-power-on-sequence = "1", "vddio", "3", "vdd","3", "gpio1", "3", "gpio2", "3", "vci", "10";
	oplus,panel-power-off-sequence = "1", "vci", "3", "vdd", "3", "vddio", "0", "gpio2", "3", "gpio1", "1";

	//enable mipi strength
	oplus,enhance_mipi_strength;

	/* BRIGHTNESS CONFIG */
	qcom,mdss-dsi-bl-pmic-control-type = "bl_ctrl_dcs";
	qcom,bl-update-flag = "delay_until_first_frame";
	qcom,mdss-dsi-bl-inverted-dbv;
	qcom,mdss-dsi-bl-min-level = <1>;
	qcom,mdss-dsi-bl-max-level = <4094>;
	qcom,mdss-brightness-max-level = <4094>;
	oplus,dsi-bl-normal-max-level = <3515>;
	oplus,dsi-brightness-normal-max-level = <3515>;
	oplus,dsi-dc-backlight-threshold = <1960>;
	oplus,dsi-brightness-default-level = <1638>;

	/* ESD CONFIG */
	qcom,esd-check-enabled;
	oplus,esd-check-flag-enabled;
	qcom,mdss-dsi-panel-status-check-mode = "reg_read";
	qcom,mdss-dsi-panel-status-command = [
		06 00 00 00 00 00 01 0A
	];
	qcom,mdss-dsi-panel-status-command-state = "dsi_lp_mode";
	qcom,mdss-dsi-panel-status-value = <
		0x9C
	>;
	qcom,mdss-dsi-panel-status-read-length = <1>;
	oplus,mdss-dsi-panel-status-match-modes = <0x00000000>;

	/* MIPI ERR check config */
	/*  BIT(0): enable/disable check
	 ** BIT(1): enable/disable page switch
	 */
	oplus,mipi-err-check-config = <0x03>; // 0b0000'0011
	oplus,mipi-err-check-reg = [
		0E
	];
	oplus,mipi-err-check-value = [
		00
	];
	oplus,mipi-err-check-count = [
		01
	];
	/* 32-bit binary flag
	 ** Bit value identified how to match the return value of each register.
	 ** The value 0(default) means equal, and the value 1 means not equal.
	 */
	oplus,mipi-err-check-match-modes = <0x00000000>;

	/* FACTORY CONFIG */
	oplus,mdss-dsi-vendor-name = "A0020";
	oplus,mdss-dsi-manufacture = "P_7";
	oplus,color_vivid_status;
	oplus,color_srgb_status;
	//oplus,color_softiris_status;
	oplus,color_oplus_calibrate_status;
	oplus,color_dual_brightness_status;
	oplus,color_2nit_status;
	oplus,color_loading_status;
	//oplus,color_nature_profession_status;
	oplus,mdss-dsi-panel-type = <2>;

	/* OPLUS FEATURES CONFIG */
	oplus,dsi-serial-number-enabled;
	oplus,dsi-serial-number-switch-page;
	oplus,dsi-serial-number-index= <0>;
	oplus,dsi-serial-number-reg= <0x80>;
	oplus,dsi-serial-number-read-count= <7>;
	oplus,dsi-serial-number-base-year = <2020>;

	/* btb-sn config */
	oplus,dsi-btb-sn-enabled;
	oplus,dsi-btb-sn-switch-page;
	oplus,dsi-btb-sn-reg= <0x82>;
	oplus,dsi-btb-sn-index= <0>;
	oplus,dsi-btb-sn-read-count= <32>;

	qcom,ulps-enabled;
	qcom,dsi-select-clocks = "pll_byte_clk0", "pll_dsi_clk0";

	oplus,vreg_ctrl_flag;

	/* ofp config */
	oplus,ofp-fp-type = <0xc0>;
	oplus,ofp-longrui-aod-config = <0x0E>;
	oplus,ofp-need-to-wait-data-before-aod-on;
	oplus,ofp-aod-off-frame-cost = <1>;
	/* adfr config */
	oplus,adfr-config = <0x6e41>;  // 0b0110'1110'0100'0001
	oplus,adfr-test-te-gpio = <&tlmm 85 0>;
	/* just for qsync enable*/
	qcom,qsync-enable;
	qcom,mdss-dsi-qsync-min-refresh-rate = <30>;

	// qcom,dsi-dyn-clk-enable;

	qcom,mdss-dsi-display-timings {
		timing@sdc_fhd_120 { /* FHD+ 120hz 1112.6Mbps */
			qcom,mdss-dsi-panel-phy-timings = [00 24 0A 0A 1A 18 0A 0A 09 02 04 00 1E 0F];
			qcom,display-topology = <1 1 1>,<2 2 1>;
			qcom,default-topology-index = <1>;
			qcom,partial-update-enabled = "single_roi";
			qcom,panel-roi-alignment = <1272 88 1272 88 1272 88>;
			qcom,dsi-mode-te-width-us = <315>;
		};
		timing@sdc_fhd_90 { /* FHD+ 90hz 1112.6Mbps */
			qcom,mdss-dsi-panel-phy-timings = [00 24 0A 0A 1A 18 0A 0A 09 02 04 00 1E 0F];
			qcom,display-topology = <1 1 1>,<2 2 1>;
			qcom,default-topology-index = <1>;
			qcom,partial-update-enabled = "single_roi";
			qcom,panel-roi-alignment = <1272 88 1272 88 1272 88>;
			qcom,dsi-mode-te-width-us = <315>;
		};
		timing@sdc_fhd_60 { /* FHD+ 60hz 1112.6Mbps */
			qcom,mdss-dsi-panel-phy-timings = [00 24 0A 0A 1A 18 0A 0A 09 02 04 00 1E 0F];
			qcom,display-topology = <1 1 1>,<2 2 1>;
			qcom,default-topology-index = <1>;
			qcom,partial-update-enabled = "single_roi";
			qcom,panel-roi-alignment = <1272 88 1272 88 1272 88>;
			qcom,dsi-mode-te-width-us = <315>;
		};
		timing@sdc_fhd_144 { /* FHD+ 144hz 1363.2Mbps */
			qcom,mdss-dsi-panel-phy-timings = [00 2C 0C 0C 1D 1A 0C 0C 0B 02 04 00 24 11];
			qcom,display-topology = <1 1 1>,<2 2 1>;
			qcom,default-topology-index = <1>;
			qcom,partial-update-enabled = "single_roi";
			qcom,panel-roi-alignment = <1272 88 1272 88 1272 88>;
			qcom,dsi-mode-te-width-us = <315>;
		};
		timing@sdc_fhd_165 { /* FHD+ 165hz 1363.2Mbps */
			qcom,mdss-dsi-panel-phy-timings = [00 2C 0C 0C 1D 1A 0C 0C 0B 02 04 00 24 11];
			qcom,display-topology = <1 1 1>,<2 2 1>;
			qcom,default-topology-index = <1>;
			qcom,partial-update-enabled = "single_roi";
			qcom,panel-roi-alignment = <1272 88 1272 88 1272 88>;
			qcom,dsi-mode-te-width-us = <315>;
		};
		timing@oplus_fhd_120 { /* FHD+ 120hz 1112.6Mbps */
			qcom,mdss-dsi-panel-phy-timings = [00 24 0A 0A 1A 18 0A 0A 09 02 04 00 1E 0F];
			qcom,display-topology = <1 1 1>,<2 2 1>;
			qcom,default-topology-index = <1>;
			qcom,dsi-mode-te-width-us = <315>;
		};
	};
};

&dsi_panel_AA601_P_7_A0020_dsc_cmd {
	qcom,mdss-dsi-display-timings {
		timing@sdc_fhd_120 { /* FHD+ 120hz 1094.4Mbps */
			/* standard adfr */
			qcom,disable-rsc-solver;
			qcom,mdss-dsi-h-sync-skew = <0>;
			oplus,adfr-min-fps-mapping-table = <120 60 30 20 10 1>;
			// oplus,adfr-idle-off-min-fps = <20>;
			oplus,adfr-high-precision-fps-mapping-table = <120 90 72 60>;

			qcom,mdss-dsi-adfr-min-fps-0-command = [
				39 00 00 40 00 00 04 FF 5A A5 2D
				39 00 00 40 00 00 03 83 00 00
				39 00 00 00 00 00 04 FF 5A A5 00
			];
			qcom,mdss-dsi-adfr-min-fps-1-command = [
				39 00 00 40 00 00 04 FF 5A A5 2D
				39 00 00 40 00 00 03 83 01 00
				39 00 00 00 00 00 04 FF 5A A5 00
			];
			qcom,mdss-dsi-adfr-min-fps-2-command = [
				39 00 00 40 00 00 04 FF 5A A5 2D
				39 00 00 40 00 00 03 83 03 00
				39 00 00 00 00 00 04 FF 5A A5 00
			];
			qcom,mdss-dsi-adfr-min-fps-3-command = [
				39 00 00 40 00 00 04 FF 5A A5 2D
				39 00 00 40 00 00 03 83 05 00
				39 00 00 00 00 00 04 FF 5A A5 00
			];
			qcom,mdss-dsi-adfr-min-fps-4-command = [
				39 00 00 40 00 00 04 FF 5A A5 2D
				39 00 00 40 00 00 03 83 0B 00
				39 00 00 00 00 00 04 FF 5A A5 00
			];
			qcom,mdss-dsi-adfr-min-fps-5-command = [
				39 00 00 40 00 00 04 FF 5A A5 2D
				39 00 00 40 00 00 03 83 77 00
				39 00 00 00 00 00 04 FF 5A A5 00
			];
			qcom,mdss-dsi-hpwm-adfr-min-fps-0-command = [
				39 00 00 40 00 00 04 FF 5A A5 2D
				39 00 00 40 00 00 03 83 00 00
				39 00 00 00 00 00 04 FF 5A A5 00
			];
			qcom,mdss-dsi-hpwm-adfr-min-fps-1-command = [
				39 00 00 40 00 00 04 FF 5A A5 2D
				39 00 00 40 00 00 03 83 01 00
				39 00 00 00 00 00 04 FF 5A A5 00
			];
			qcom,mdss-dsi-hpwm-adfr-min-fps-2-command = [
				39 00 00 40 00 00 04 FF 5A A5 2D
				39 00 00 40 00 00 03 83 03 00
				39 00 00 00 00 00 04 FF 5A A5 00
			];
			qcom,mdss-dsi-hpwm-adfr-min-fps-3-command = [
				39 00 00 40 00 00 04 FF 5A A5 2D
				39 00 00 40 00 00 03 83 05 00
				39 00 00 00 00 00 04 FF 5A A5 00
			];
			qcom,mdss-dsi-hpwm-adfr-min-fps-4-command = [
				39 00 00 40 00 00 04 FF 5A A5 2D
				39 00 00 40 00 00 03 83 0B 00
				39 00 00 00 00 00 04 FF 5A A5 00
			];
			qcom,mdss-dsi-hpwm-adfr-min-fps-5-command = [
				39 00 00 40 00 00 04 FF 5A A5 2D
				39 00 00 40 00 00 03 83 77 00
				39 00 00 00 00 00 04 FF 5A A5 00
			];
			qcom,mdss-dsi-bigdc-adfr-min-fps-0-command = [
				39 00 00 40 00 00 04 FF 5A A5 2D
				39 00 00 40 00 00 03 84 00 00
				39 00 00 00 00 00 04 FF 5A A5 00
			];
			qcom,mdss-dsi-bigdc-adfr-min-fps-1-command = [
				39 00 00 40 00 00 04 FF 5A A5 2D
				39 00 00 40 00 00 03 84 01 00
				39 00 00 00 00 00 04 FF 5A A5 00
			];
			qcom,mdss-dsi-bigdc-adfr-min-fps-2-command = [
				39 00 00 40 00 00 04 FF 5A A5 2D
				39 00 00 40 00 00 03 84 03 00
				39 00 00 00 00 00 04 FF 5A A5 00
			];
			qcom,mdss-dsi-bigdc-adfr-min-fps-3-command = [
				39 00 00 40 00 00 04 FF 5A A5 2D
				39 00 00 40 00 00 03 84 05 00
				39 00 00 00 00 00 04 FF 5A A5 00
			];
			qcom,mdss-dsi-bigdc-adfr-min-fps-4-command = [
				39 00 00 40 00 00 04 FF 5A A5 2D
				39 00 00 40 00 00 03 84 0B 00
				39 00 00 00 00 00 04 FF 5A A5 00
			];
			qcom,mdss-dsi-bigdc-adfr-min-fps-5-command = [
				39 00 00 40 00 00 04 FF 5A A5 2D
				39 00 00 40 00 00 03 84 77 00
				39 00 00 00 00 00 04 FF 5A A5 00
			];
			qcom,mdss-dsi-adfr-min-fps-0-command-state = "dsi_hs_mode";
			qcom,mdss-dsi-adfr-min-fps-1-command-state = "dsi_hs_mode";
			qcom,mdss-dsi-adfr-min-fps-2-command-state = "dsi_hs_mode";
			qcom,mdss-dsi-adfr-min-fps-3-command-state = "dsi_hs_mode";
			qcom,mdss-dsi-adfr-min-fps-4-command-state = "dsi_hs_mode";
			qcom,mdss-dsi-adfr-min-fps-5-command-state = "dsi_hs_mode";
			qcom,mdss-dsi-hpwm-adfr-min-fps-0-command-state = "dsi_hs_mode";
			qcom,mdss-dsi-hpwm-adfr-min-fps-1-command-state = "dsi_hs_mode";
			qcom,mdss-dsi-hpwm-adfr-min-fps-2-command-state = "dsi_hs_mode";
			qcom,mdss-dsi-hpwm-adfr-min-fps-3-command-state = "dsi_hs_mode";
			qcom,mdss-dsi-hpwm-adfr-min-fps-4-command-state = "dsi_hs_mode";
			qcom,mdss-dsi-hpwm-adfr-min-fps-5-command-state = "dsi_hs_mode";
			qcom,mdss-dsi-bigdc-adfr-min-fps-0-command-state = "dsi_hs_mode";
			qcom,mdss-dsi-bigdc-adfr-min-fps-1-command-state = "dsi_hs_mode";
			qcom,mdss-dsi-bigdc-adfr-min-fps-2-command-state = "dsi_hs_mode";
			qcom,mdss-dsi-bigdc-adfr-min-fps-3-command-state = "dsi_hs_mode";
			qcom,mdss-dsi-bigdc-adfr-min-fps-4-command-state = "dsi_hs_mode";
			qcom,mdss-dsi-bigdc-adfr-min-fps-5-command-state = "dsi_hs_mode";
		};
		timing@sdc_fhd_90 {
			/* standard adfr */
			qcom,disable-rsc-solver;
			qcom,mdss-dsi-h-sync-skew = <0>;
			oplus,adfr-min-fps-mapping-table = <90 45 30 15 10 1>;
			// oplus,adfr-idle-off-min-fps = <30>;

			qcom,mdss-dsi-adfr-min-fps-0-command = [
				39 00 00 40 00 00 04 FF 5A A5 2D
				39 00 00 40 00 00 03 85 00 00
				39 00 00 00 00 00 04 FF 5A A5 00
			];
			qcom,mdss-dsi-adfr-min-fps-1-command = [
				39 00 00 40 00 00 04 FF 5A A5 2D
				39 00 00 40 00 00 03 85 01 00
				39 00 00 00 00 00 04 FF 5A A5 00
			];
			qcom,mdss-dsi-adfr-min-fps-2-command = [
				39 00 00 40 00 00 04 FF 5A A5 2D
				39 00 00 40 00 00 03 85 02 00
				39 00 00 00 00 00 04 FF 5A A5 00
			];
			qcom,mdss-dsi-adfr-min-fps-3-command = [
				39 00 00 40 00 00 04 FF 5A A5 2D
				39 00 00 40 00 00 03 85 05 00
				39 00 00 00 00 00 04 FF 5A A5 00
			];
			qcom,mdss-dsi-adfr-min-fps-4-command = [
				39 00 00 40 00 00 04 FF 5A A5 2D
				39 00 00 40 00 00 03 85 08 00
				39 00 00 00 00 00 04 FF 5A A5 00
			];
			qcom,mdss-dsi-adfr-min-fps-5-command = [
				39 00 00 40 00 00 04 FF 5A A5 2D
				39 00 00 40 00 00 03 85 59 00
				39 00 00 00 00 00 04 FF 5A A5 00
			];
			qcom,mdss-dsi-hpwm-adfr-min-fps-0-command = [
				39 00 00 40 00 00 04 FF 5A A5 2D
				39 00 00 40 00 00 03 85 00 00
				39 00 00 00 00 00 04 FF 5A A5 00
			];
			qcom,mdss-dsi-hpwm-adfr-min-fps-1-command = [
				39 00 00 40 00 00 04 FF 5A A5 2D
				39 00 00 40 00 00 03 85 01 00
				39 00 00 00 00 00 04 FF 5A A5 00
			];
			qcom,mdss-dsi-hpwm-adfr-min-fps-2-command = [
				39 00 00 40 00 00 04 FF 5A A5 2D
				39 00 00 40 00 00 03 85 02 00
				39 00 00 00 00 00 04 FF 5A A5 00
			];
			qcom,mdss-dsi-hpwm-adfr-min-fps-3-command = [
				39 00 00 40 00 00 04 FF 5A A5 2D
				39 00 00 40 00 00 03 85 05 00
				39 00 00 00 00 00 04 FF 5A A5 00
			];
			qcom,mdss-dsi-hpwm-adfr-min-fps-4-command = [
				39 00 00 40 00 00 04 FF 5A A5 2D
				39 00 00 40 00 00 03 85 08 00
				39 00 00 00 00 00 04 FF 5A A5 00
			];
			qcom,mdss-dsi-hpwm-adfr-min-fps-5-command = [
				39 00 00 40 00 00 04 FF 5A A5 2D
				39 00 00 40 00 00 03 85 59 00
				39 00 00 00 00 00 04 FF 5A A5 00
			];
			qcom,mdss-dsi-bigdc-adfr-min-fps-0-command = [
				39 00 00 40 00 00 04 FF 5A A5 2D
				39 00 00 40 00 00 03 86 00 00
				39 00 00 00 00 00 04 FF 5A A5 00
			];
			qcom,mdss-dsi-bigdc-adfr-min-fps-1-command = [
				39 00 00 40 00 00 04 FF 5A A5 2D
				39 00 00 40 00 00 03 86 01 00
				39 00 00 00 00 00 04 FF 5A A5 00
			];
			qcom,mdss-dsi-bigdc-adfr-min-fps-2-command = [
				39 00 00 40 00 00 04 FF 5A A5 2D
				39 00 00 40 00 00 03 86 02 00
				39 00 00 00 00 00 04 FF 5A A5 00
			];
			qcom,mdss-dsi-bigdc-adfr-min-fps-3-command = [
				39 00 00 40 00 00 04 FF 5A A5 2D
				39 00 00 40 00 00 03 86 05 00
				39 00 00 00 00 00 04 FF 5A A5 00
			];
			qcom,mdss-dsi-bigdc-adfr-min-fps-4-command = [
				39 00 00 40 00 00 04 FF 5A A5 2D
				39 00 00 40 00 00 03 86 08 00
				39 00 00 00 00 00 04 FF 5A A5 00
			];
			qcom,mdss-dsi-bigdc-adfr-min-fps-5-command = [
				39 00 00 40 00 00 04 FF 5A A5 2D
				39 00 00 40 00 00 03 86 59 00
				39 00 00 00 00 00 04 FF 5A A5 00
			];

			qcom,mdss-dsi-adfr-min-fps-0-command-state = "dsi_hs_mode";
			qcom,mdss-dsi-adfr-min-fps-1-command-state = "dsi_hs_mode";
			qcom,mdss-dsi-adfr-min-fps-2-command-state = "dsi_hs_mode";
			qcom,mdss-dsi-adfr-min-fps-3-command-state = "dsi_hs_mode";
			qcom,mdss-dsi-adfr-min-fps-4-command-state = "dsi_hs_mode";
			qcom,mdss-dsi-adfr-min-fps-5-command-state = "dsi_hs_mode";
			qcom,mdss-dsi-hpwm-adfr-min-fps-0-command-state = "dsi_hs_mode";
			qcom,mdss-dsi-hpwm-adfr-min-fps-1-command-state = "dsi_hs_mode";
			qcom,mdss-dsi-hpwm-adfr-min-fps-2-command-state = "dsi_hs_mode";
			qcom,mdss-dsi-hpwm-adfr-min-fps-3-command-state = "dsi_hs_mode";
			qcom,mdss-dsi-hpwm-adfr-min-fps-4-command-state = "dsi_hs_mode";
			qcom,mdss-dsi-hpwm-adfr-min-fps-5-command-state = "dsi_hs_mode";
			qcom,mdss-dsi-bigdc-adfr-min-fps-0-command-state = "dsi_hs_mode";
			qcom,mdss-dsi-bigdc-adfr-min-fps-1-command-state = "dsi_hs_mode";
			qcom,mdss-dsi-bigdc-adfr-min-fps-2-command-state = "dsi_hs_mode";
			qcom,mdss-dsi-bigdc-adfr-min-fps-3-command-state = "dsi_hs_mode";
			qcom,mdss-dsi-bigdc-adfr-min-fps-4-command-state = "dsi_hs_mode";
			qcom,mdss-dsi-bigdc-adfr-min-fps-5-command-state = "dsi_hs_mode";
		};
		timing@sdc_fhd_60 {
			/* standard adfr */
			qcom,disable-rsc-solver;
			qcom,mdss-dsi-h-sync-skew = <1>;
			oplus,adfr-min-fps-mapping-table = <60 40 30 20 10 1>;
			// oplus,adfr-idle-off-min-fps = <20>;

			qcom,mdss-dsi-adfr-min-fps-0-command = [
				39 00 00 40 00 00 04 FF 5A A5 2D
				39 00 00 40 00 00 03 83 01 00
				39 00 00 00 00 00 04 FF 5A A5 00
			];
			qcom,mdss-dsi-adfr-min-fps-1-command = [
				39 00 00 40 00 00 04 FF 5A A5 2D
				39 00 00 40 00 00 03 83 02 00
				39 00 00 00 00 00 04 FF 5A A5 00
			];
			qcom,mdss-dsi-adfr-min-fps-2-command = [
				39 00 00 40 00 00 04 FF 5A A5 2D
				39 00 00 40 00 00 03 83 03 00
				39 00 00 00 00 00 04 FF 5A A5 00
			];
			qcom,mdss-dsi-adfr-min-fps-3-command = [
				39 00 00 40 00 00 04 FF 5A A5 2D
				39 00 00 40 00 00 03 83 05 00
				39 00 00 00 00 00 04 FF 5A A5 00
			];
			qcom,mdss-dsi-adfr-min-fps-4-command = [
				39 00 00 40 00 00 04 FF 5A A5 2D
				39 00 00 40 00 00 03 83 0B 00
				39 00 00 00 00 00 04 FF 5A A5 00
			];
			qcom,mdss-dsi-adfr-min-fps-5-command = [
				39 00 00 40 00 00 04 FF 5A A5 2D
				39 00 00 40 00 00 03 83 77 00
				39 00 00 00 00 00 04 FF 5A A5 00
			];
			qcom,mdss-dsi-hpwm-adfr-min-fps-0-command = [
				39 00 00 40 00 00 04 FF 5A A5 2D
				39 00 00 40 00 00 03 83 01 00
				39 00 00 00 00 00 04 FF 5A A5 00
			];
			qcom,mdss-dsi-hpwm-adfr-min-fps-1-command = [
				39 00 00 40 00 00 04 FF 5A A5 2D
				39 00 00 40 00 00 03 83 02 00
				39 00 00 00 00 00 04 FF 5A A5 00
			];
			qcom,mdss-dsi-hpwm-adfr-min-fps-2-command = [
				39 00 00 40 00 00 04 FF 5A A5 2D
				39 00 00 40 00 00 03 83 03 00
				39 00 00 00 00 00 04 FF 5A A5 00
			];
			qcom,mdss-dsi-hpwm-adfr-min-fps-3-command = [
				39 00 00 40 00 00 04 FF 5A A5 2D
				39 00 00 40 00 00 03 83 05 00
				39 00 00 00 00 00 04 FF 5A A5 00
			];
			qcom,mdss-dsi-hpwm-adfr-min-fps-4-command = [
				39 00 00 40 00 00 04 FF 5A A5 2D
				39 00 00 40 00 00 03 83 0B 00
				39 00 00 00 00 00 04 FF 5A A5 00
			];
			qcom,mdss-dsi-hpwm-adfr-min-fps-5-command = [
				39 00 00 40 00 00 04 FF 5A A5 2D
				39 00 00 40 00 00 03 83 77 00
				39 00 00 00 00 00 04 FF 5A A5 00
			];
			qcom,mdss-dsi-bigdc-adfr-min-fps-0-command = [
				39 00 00 40 00 00 04 FF 5A A5 2D
				39 00 00 40 00 00 03 84 01 00
				39 00 00 00 00 00 04 FF 5A A5 00
			];
			qcom,mdss-dsi-bigdc-adfr-min-fps-1-command = [
				39 00 00 40 00 00 04 FF 5A A5 2D
				39 00 00 40 00 00 03 84 02 00
				39 00 00 00 00 00 04 FF 5A A5 00
			];
			qcom,mdss-dsi-bigdc-adfr-min-fps-2-command = [
				39 00 00 40 00 00 04 FF 5A A5 2D
				39 00 00 40 00 00 03 84 03 00
				39 00 00 00 00 00 04 FF 5A A5 00
			];
			qcom,mdss-dsi-bigdc-adfr-min-fps-3-command = [
				39 00 00 40 00 00 04 FF 5A A5 2D
				39 00 00 40 00 00 03 84 05 00
				39 00 00 00 00 00 04 FF 5A A5 00
			];
			qcom,mdss-dsi-bigdc-adfr-min-fps-4-command = [
				39 00 00 40 00 00 04 FF 5A A5 2D
				39 00 00 40 00 00 03 84 0B 00
				39 00 00 00 00 00 04 FF 5A A5 00
			];
			qcom,mdss-dsi-bigdc-adfr-min-fps-5-command = [
				39 00 00 40 00 00 04 FF 5A A5 2D
				39 00 00 40 00 00 03 84 77 00
				39 00 00 00 00 00 04 FF 5A A5 00
			];

			qcom,mdss-dsi-adfr-min-fps-0-command-state = "dsi_hs_mode";
			qcom,mdss-dsi-adfr-min-fps-1-command-state = "dsi_hs_mode";
			qcom,mdss-dsi-adfr-min-fps-2-command-state = "dsi_hs_mode";
			qcom,mdss-dsi-adfr-min-fps-3-command-state = "dsi_hs_mode";
			qcom,mdss-dsi-adfr-min-fps-4-command-state = "dsi_hs_mode";
			qcom,mdss-dsi-adfr-min-fps-5-command-state = "dsi_hs_mode";
			qcom,mdss-dsi-hpwm-adfr-min-fps-0-command-state = "dsi_hs_mode";
			qcom,mdss-dsi-hpwm-adfr-min-fps-1-command-state = "dsi_hs_mode";
			qcom,mdss-dsi-hpwm-adfr-min-fps-2-command-state = "dsi_hs_mode";
			qcom,mdss-dsi-hpwm-adfr-min-fps-3-command-state = "dsi_hs_mode";
			qcom,mdss-dsi-hpwm-adfr-min-fps-4-command-state = "dsi_hs_mode";
			qcom,mdss-dsi-hpwm-adfr-min-fps-5-command-state = "dsi_hs_mode";
			qcom,mdss-dsi-bigdc-adfr-min-fps-0-command-state = "dsi_hs_mode";
			qcom,mdss-dsi-bigdc-adfr-min-fps-1-command-state = "dsi_hs_mode";
			qcom,mdss-dsi-bigdc-adfr-min-fps-2-command-state = "dsi_hs_mode";
			qcom,mdss-dsi-bigdc-adfr-min-fps-3-command-state = "dsi_hs_mode";
			qcom,mdss-dsi-bigdc-adfr-min-fps-4-command-state = "dsi_hs_mode";
			qcom,mdss-dsi-bigdc-adfr-min-fps-5-command-state = "dsi_hs_mode";
		};
		timing@sdc_fhd_144 {
			/* standard adfr */
			qcom,disable-rsc-solver;
			qcom,mdss-dsi-h-sync-skew = <0>;
		};
		timing@sdc_fhd_165 {
			/* standard adfr */
			qcom,disable-rsc-solver;
			qcom,mdss-dsi-h-sync-skew = <0>;
		};
		timing@oplus_fhd_120 {
			/* oplus adfr */
			qcom,disable-rsc-solver;
			qcom,mdss-dsi-h-sync-skew = <2>;
			oplus,adfr-min-fps-mapping-table = <120 60 30 20 10 1>;
			// oplus,adfr-idle-off-min-fps = <20>;
			oplus,adfr-high-precision-fps-mapping-table = <120 90 72 60>;

			qcom,mdss-dsi-adfr-min-fps-0-command = [
				39 00 00 40 00 00 04 FF 5A A5 2D
				39 00 00 40 00 00 03 83 00 00
				39 00 00 00 00 00 04 FF 5A A5 00
			];
			qcom,mdss-dsi-adfr-min-fps-1-command = [
				39 00 00 40 00 00 04 FF 5A A5 2D
				39 00 00 40 00 00 03 83 01 00
				39 00 00 00 00 00 04 FF 5A A5 00
			];
			qcom,mdss-dsi-adfr-min-fps-2-command = [
				39 00 00 40 00 00 04 FF 5A A5 2D
				39 00 00 40 00 00 03 83 03 00
				39 00 00 00 00 00 04 FF 5A A5 00
			];
			qcom,mdss-dsi-adfr-min-fps-3-command = [
				39 00 00 40 00 00 04 FF 5A A5 2D
				39 00 00 40 00 00 03 83 05 00
				39 00 00 00 00 00 04 FF 5A A5 00
			];
			qcom,mdss-dsi-adfr-min-fps-4-command = [
				39 00 00 40 00 00 04 FF 5A A5 2D
				39 00 00 40 00 00 03 83 0B 00
				39 00 00 00 00 00 04 FF 5A A5 00
			];
			qcom,mdss-dsi-adfr-min-fps-5-command = [
				39 00 00 40 00 00 04 FF 5A A5 2D
				39 00 00 40 00 00 03 83 77 00
				39 00 00 00 00 00 04 FF 5A A5 00
			];
			qcom,mdss-dsi-hpwm-adfr-min-fps-0-command = [
				39 00 00 40 00 00 04 FF 5A A5 2D
				39 00 00 40 00 00 03 83 00 00
				39 00 00 00 00 00 04 FF 5A A5 00
			];
			qcom,mdss-dsi-hpwm-adfr-min-fps-1-command = [
				39 00 00 40 00 00 04 FF 5A A5 2D
				39 00 00 40 00 00 03 83 01 00
				39 00 00 00 00 00 04 FF 5A A5 00
			];
			qcom,mdss-dsi-hpwm-adfr-min-fps-2-command = [
				39 00 00 40 00 00 04 FF 5A A5 2D
				39 00 00 40 00 00 03 83 03 00
				39 00 00 00 00 00 04 FF 5A A5 00
			];
			qcom,mdss-dsi-hpwm-adfr-min-fps-3-command = [
				39 00 00 40 00 00 04 FF 5A A5 2D
				39 00 00 40 00 00 03 83 05 00
				39 00 00 00 00 00 04 FF 5A A5 00
			];
			qcom,mdss-dsi-hpwm-adfr-min-fps-4-command = [
				39 00 00 40 00 00 04 FF 5A A5 2D
				39 00 00 40 00 00 03 83 0B 00
				39 00 00 00 00 00 04 FF 5A A5 00
			];
			qcom,mdss-dsi-hpwm-adfr-min-fps-5-command = [
				39 00 00 40 00 00 04 FF 5A A5 2D
				39 00 00 40 00 00 03 83 77 00
				39 00 00 00 00 00 04 FF 5A A5 00
			];
			qcom,mdss-dsi-bigdc-adfr-min-fps-0-command = [
				39 00 00 40 00 00 04 FF 5A A5 2D
				39 00 00 40 00 00 03 84 00 00
				39 00 00 00 00 00 04 FF 5A A5 00
			];
			qcom,mdss-dsi-bigdc-adfr-min-fps-1-command = [
				39 00 00 40 00 00 04 FF 5A A5 2D
				39 00 00 40 00 00 03 84 01 00
				39 00 00 00 00 00 04 FF 5A A5 00
			];
			qcom,mdss-dsi-bigdc-adfr-min-fps-2-command = [
				39 00 00 40 00 00 04 FF 5A A5 2D
				39 00 00 40 00 00 03 84 03 00
				39 00 00 00 00 00 04 FF 5A A5 00
			];
			qcom,mdss-dsi-bigdc-adfr-min-fps-3-command = [
				39 00 00 40 00 00 04 FF 5A A5 2D
				39 00 00 40 00 00 03 84 05 00
				39 00 00 00 00 00 04 FF 5A A5 00
			];
			qcom,mdss-dsi-bigdc-adfr-min-fps-4-command = [
				39 00 00 40 00 00 04 FF 5A A5 2D
				39 00 00 40 00 00 03 84 0B 00
				39 00 00 00 00 00 04 FF 5A A5 00
			];
			qcom,mdss-dsi-bigdc-adfr-min-fps-5-command = [
				39 00 00 40 00 00 04 FF 5A A5 2D
				39 00 00 40 00 00 03 84 77 00
				39 00 00 00 00 00 04 FF 5A A5 00
			];

			qcom,mdss-dsi-adfr-min-fps-0-command-state = "dsi_hs_mode";
			qcom,mdss-dsi-adfr-min-fps-1-command-state = "dsi_hs_mode";
			qcom,mdss-dsi-adfr-min-fps-2-command-state = "dsi_hs_mode";
			qcom,mdss-dsi-adfr-min-fps-3-command-state = "dsi_hs_mode";
			qcom,mdss-dsi-adfr-min-fps-4-command-state = "dsi_hs_mode";
			qcom,mdss-dsi-adfr-min-fps-5-command-state = "dsi_hs_mode";
			qcom,mdss-dsi-hpwm-adfr-min-fps-0-command-state = "dsi_hs_mode";
			qcom,mdss-dsi-hpwm-adfr-min-fps-1-command-state = "dsi_hs_mode";
			qcom,mdss-dsi-hpwm-adfr-min-fps-2-command-state = "dsi_hs_mode";
			qcom,mdss-dsi-hpwm-adfr-min-fps-3-command-state = "dsi_hs_mode";
			qcom,mdss-dsi-hpwm-adfr-min-fps-4-command-state = "dsi_hs_mode";
			qcom,mdss-dsi-hpwm-adfr-min-fps-5-command-state = "dsi_hs_mode";
			qcom,mdss-dsi-bigdc-adfr-min-fps-0-command-state = "dsi_hs_mode";
			qcom,mdss-dsi-bigdc-adfr-min-fps-1-command-state = "dsi_hs_mode";
			qcom,mdss-dsi-bigdc-adfr-min-fps-2-command-state = "dsi_hs_mode";
			qcom,mdss-dsi-bigdc-adfr-min-fps-3-command-state = "dsi_hs_mode";
			qcom,mdss-dsi-bigdc-adfr-min-fps-4-command-state = "dsi_hs_mode";
			qcom,mdss-dsi-bigdc-adfr-min-fps-5-command-state = "dsi_hs_mode";
		};
	};
};

&dsi_panel_AA601_P_7_A0020_dsc_cmd {
	qcom,panel_voltage_vddi_name = "vddio";
	qcom,panel_voltage_vddi = <0 1800000 1850000 1950000>;
	qcom,panel_voltage_vddr_name = "vddio";
	qcom,panel_voltage_vddr = <1 1800000 1850000 1950000>;
};

&dsi_panel_AA601_P_7_A0020_dsc_cmd{
	oplus,adfr-oa-use-fixed-te;
	/* demura dbv config */

	oplus,panel-60hz-timing-switch-frame-delay;

	/* pwm config */
	/*	oplus,pwm-switch-config:
		Bit0: pwm feature enable
		Bit1: pwm mode switch enable, need to config switch cmds
		Bit2: force enabled pwm mode switch cmd, will send mode cmd even dbv threshold cmd feature is configed
		Bit3: pwm dbv threshold pulse switch enable, need to config threshold switch cmds
		Bit4: wait te before sending pwm dbv threshold pulse switch cmd
		Bit5: replace specific cmd to other cmd while in pwm 1pulse mode
		Bit6: sending extend cmd while panel power on accroding to current pwm mode
		Bit7: sending extend cmd while timing switch accroding to current pwm pulse level
		Bit8: sending extend cmd after sending dbv threshold cmd in another thread
		...
		Bit24:support pwm mode0
		Bit25:support pwm mode1
		Bit26:support pwm mode2
	*/
	oplus,pwm-switch-config = <0x02000067>;
	/*	oplus,pwm-switch-mode0-states-info/oplus,pwm-switch-mode1-states-info:
		Specific dbv threshold and pulse info of 2 pwm mode, for pulse, 0 symbols 1pulse,
		1symbols 3pulse and 2 symbols 18pulse. The format should be 1 dbv threshold info with
		2 pwm pulse levels left and right(for example, <2 1087 1> means 18pulse while dbv <= 1087
		and 3pulse while dbv > 1087), or only one pulse level, no threshold.
	*/
	oplus,pwm-switch-mode1-states-info = <2 1162 0>;
	oplus,pwm-switch-mode2-states-info = <0>;
	/*	oplus,pwm-mode1-cmd-switch-map/oplus,pwm-mode2-cmd-switch-map;
		Specific cmd replace relationship while in switch on(1pulse) mode. It is a string array that
		compose with cmd names, every 2 names combine 1 map. For example, map "'a', 'b'" means replace
		a to b while sending a in switch on mode.
	*/
	oplus,pwm-mode2-cmd-switch-map = "qcom,mdss-dsi-nolp-command", "qcom,mdss-dsi-aod-off-pwm-mode2-command",
			"qcom,mdss-dsi-timing-switch-command", "qcom,mdss-dsi-timming-switch-pwm-mode2-command";
	oplus,cmdq-sync-support;
	/* SPR CONFIG */
	qcom,spr-pack-type = "pentile";
};
